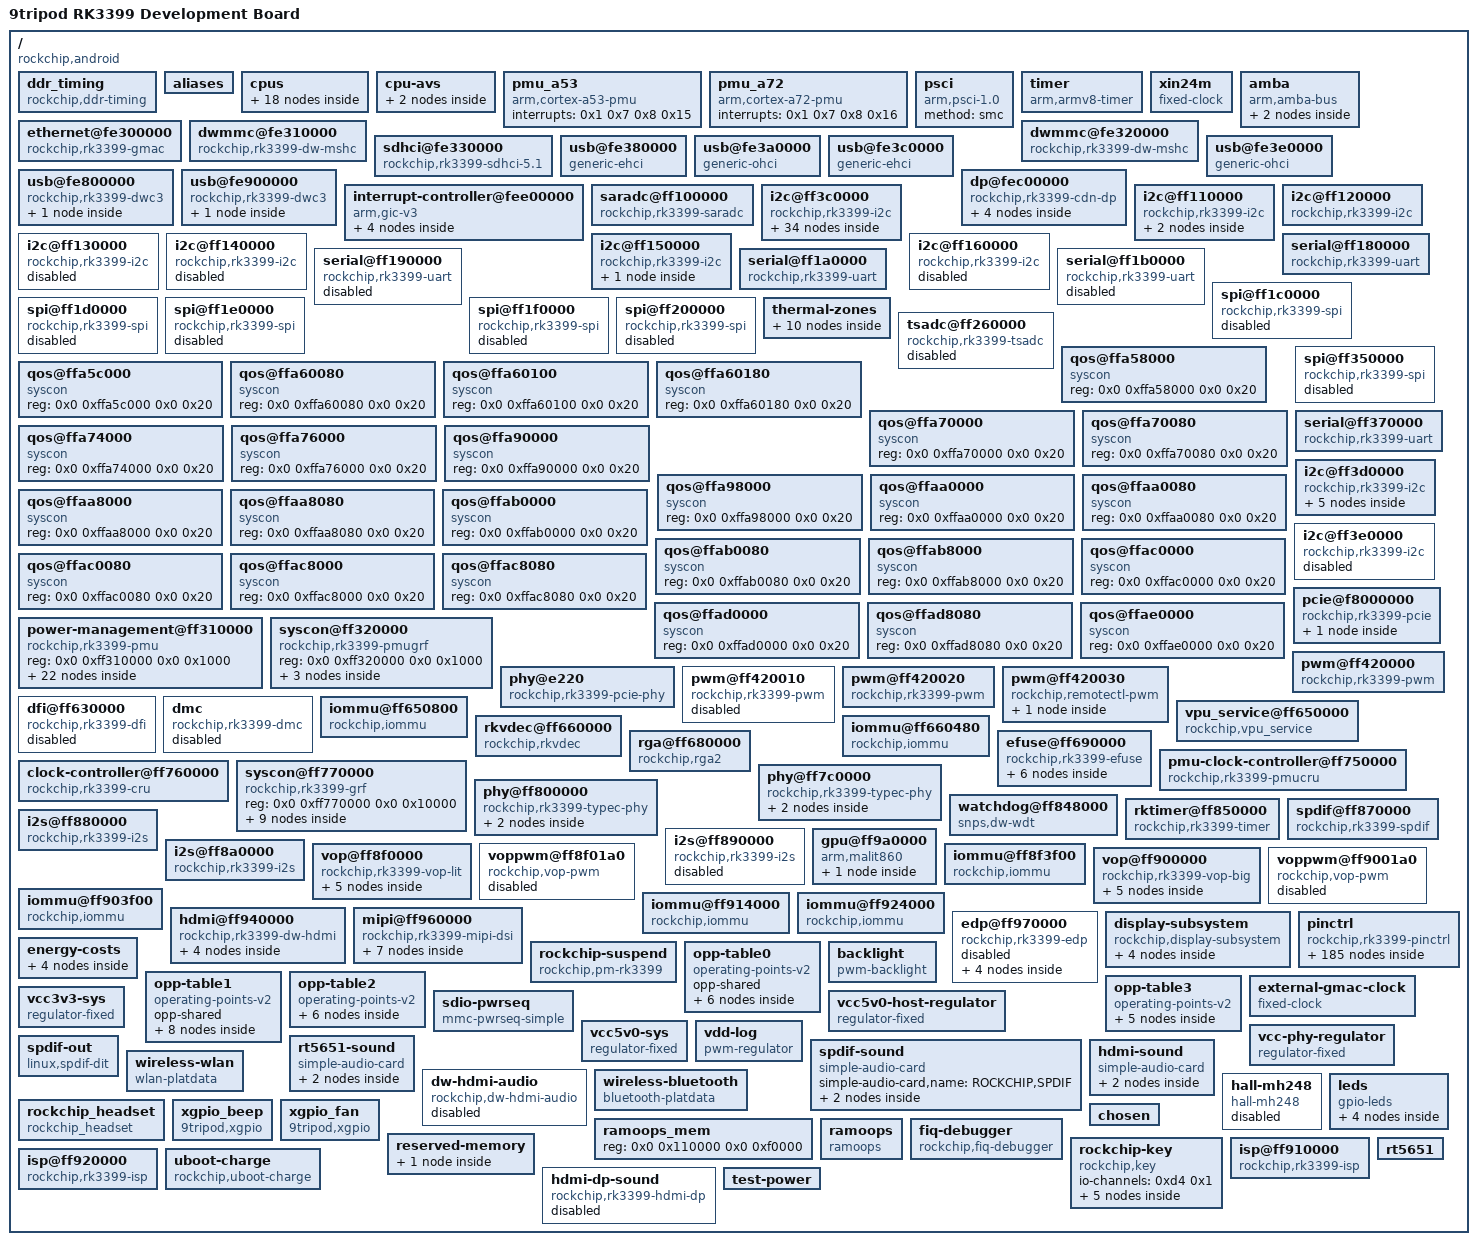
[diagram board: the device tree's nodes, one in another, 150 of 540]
/dts-v1/;

/  {

	compatible = "rockchip,android", "9tripod,x3399-development-board", "rockchip,rk3399";
	interrupt-parent = <0x1>;
	#address-cells = <0x2>;
	#size-cells = <0x2>;
	model = "9tripod RK3399 Development Board";
	ddr_timing {

		compatible = "rockchip,ddr-timing";
		ddr3_speed_bin = <0x15>;
		pd_idle = <0x0>;
		sr_idle = <0x0>;
		sr_mc_gate_idle = <0x0>;
		srpd_lite_idle = <0x0>;
		standby_idle = <0x0>;
		dram_dll_dis_freq = <0x12c>;
		phy_dll_dis_freq = <0x7d>;
		ddr3_odt_dis_freq = <0x14d>;
		ddr3_drv = <0x28>;
		ddr3_odt = <0x78>;
		phy_ddr3_ca_drv = <0x28>;
		phy_ddr3_dq_drv = <0x28>;
		phy_ddr3_odt = <0xf0>;
		lpddr3_odt_dis_freq = <0x14d>;
		lpddr3_drv = <0x22>;
		lpddr3_odt = <0xf0>;
		phy_lpddr3_ca_drv = <0x28>;
		phy_lpddr3_dq_drv = <0x28>;
		phy_lpddr3_odt = <0xf0>;
		lpddr4_odt_dis_freq = <0x14d>;
		lpddr4_drv = <0x3c>;
		lpddr4_dq_odt = <0x28>;
		lpddr4_ca_odt = <0x28>;
		phy_lpddr4_ca_drv = <0x28>;
		phy_lpddr4_ck_cs_drv = <0x50>;
		phy_lpddr4_dq_drv = <0x50>;
		phy_lpddr4_odt = <0x3c>;
		linux,phandle = <0x92>;
		phandle = <0x92>;
	};
	aliases {

		i2c0 = "/i2c@ff3c0000";
		i2c1 = "/i2c@ff110000";
		i2c2 = "/i2c@ff120000";
		i2c3 = "/i2c@ff130000";
		i2c4 = "/i2c@ff3d0000";
		i2c5 = "/i2c@ff140000";
		i2c6 = "/i2c@ff150000";
		i2c7 = "/i2c@ff160000";
		i2c8 = "/i2c@ff3e0000";
		serial0 = "/serial@ff180000";
		serial1 = "/serial@ff190000";
		serial2 = "/serial@ff1a0000";
		serial3 = "/serial@ff1b0000";
		serial4 = "/serial@ff370000";
	};
	cpus {

		#address-cells = <0x2>;
		#size-cells = <0x0>;
		cpu-map {

			cluster0 {

				core0 {

					cpu = <0x2>;
				};
				core1 {

					cpu = <0x3>;
				};
				core2 {

					cpu = <0x4>;
				};
				core3 {

					cpu = <0x5>;
				};
			};
			cluster1 {

				core0 {

					cpu = <0x6>;
				};
				core1 {

					cpu = <0x7>;
				};
			};
		};
		cpu@0 {

			device_type = "cpu";
			compatible = "arm,cortex-a53", "arm,armv8";
			reg = <0x0 0x0>;
			enable-method = "psci";
			#cooling-cells = <0x2>;
			dynamic-power-coefficient = <0x64>;
			clocks = <0x8 0x8>;
			cpu-idle-states = <0x9 0xa>;
			operating-points-v2 = <0xb>;
			sched-energy-costs = <0xc 0xd>;
			cpu-supply = <0xe>;
			linux,phandle = <0x2>;
			phandle = <0x2>;
		};
		cpu@1 {

			device_type = "cpu";
			compatible = "arm,cortex-a53", "arm,armv8";
			reg = <0x0 0x1>;
			enable-method = "psci";
			clocks = <0x8 0x8>;
			cpu-idle-states = <0x9 0xa>;
			operating-points-v2 = <0xb>;
			sched-energy-costs = <0xc 0xd>;
			cpu-supply = <0xe>;
			linux,phandle = <0x3>;
			phandle = <0x3>;
		};
		cpu@2 {

			device_type = "cpu";
			compatible = "arm,cortex-a53", "arm,armv8";
			reg = <0x0 0x2>;
			enable-method = "psci";
			clocks = <0x8 0x8>;
			cpu-idle-states = <0x9 0xa>;
			operating-points-v2 = <0xb>;
			sched-energy-costs = <0xc 0xd>;
			cpu-supply = <0xe>;
			linux,phandle = <0x4>;
			phandle = <0x4>;
		};
		cpu@3 {

			device_type = "cpu";
			compatible = "arm,cortex-a53", "arm,armv8";
			reg = <0x0 0x3>;
			enable-method = "psci";
			clocks = <0x8 0x8>;
			cpu-idle-states = <0x9 0xa>;
			operating-points-v2 = <0xb>;
			sched-energy-costs = <0xc 0xd>;
			cpu-supply = <0xe>;
			linux,phandle = <0x5>;
			phandle = <0x5>;
		};
		cpu@100 {

			device_type = "cpu";
			compatible = "arm,cortex-a72", "arm,armv8";
			reg = <0x0 0x100>;
			enable-method = "psci";
			#cooling-cells = <0x2>;
			dynamic-power-coefficient = <0x1b4>;
			clocks = <0x8 0x9>;
			cpu-idle-states = <0x9 0xa>;
			operating-points-v2 = <0xf>;
			sched-energy-costs = <0x10 0x11>;
			cpu-supply = <0x12>;
			linux,phandle = <0x6>;
			phandle = <0x6>;
		};
		cpu@101 {

			device_type = "cpu";
			compatible = "arm,cortex-a72", "arm,armv8";
			reg = <0x0 0x101>;
			enable-method = "psci";
			clocks = <0x8 0x9>;
			cpu-idle-states = <0x9 0xa>;
			operating-points-v2 = <0xf>;
			sched-energy-costs = <0x10 0x11>;
			cpu-supply = <0x12>;
			linux,phandle = <0x7>;
			phandle = <0x7>;
		};
		idle-states {

			entry-method = "psci";
			cpu-sleep {

				compatible = "arm,idle-state";
				local-timer-stop;
				arm,psci-suspend-param = <0x10000>;
				entry-latency-us = <0x78>;
				exit-latency-us = <0xfa>;
				min-residency-us = <0x384>;
				linux,phandle = <0x9>;
				phandle = <0x9>;
			};
			cluster-sleep {

				compatible = "arm,idle-state";
				local-timer-stop;
				arm,psci-suspend-param = <0x1010000>;
				entry-latency-us = <0x190>;
				exit-latency-us = <0x1f4>;
				min-residency-us = <0x7d0>;
				linux,phandle = <0xa>;
				phandle = <0xa>;
			};
		};
	};
	cpu-avs {

		cluster0-avs {

			cluster-id = <0x0>;
			min-volt = <0xc3500>;
			min-freq = <0x639c0>;
			leakage-adjust-volt = <0x0 0xfe 0x0>;
			nvmem-cells = <0x13>;
			nvmem-cell-names = "cpu_leakage";
		};
		cluster1-avs {

			cluster-id = <0x1>;
			min-volt = <0xc3500>;
			min-freq = <0x639c0>;
			leakage-adjust-volt = <0x0 0xfe 0x0>;
			nvmem-cells = <0x14>;
			nvmem-cell-names = "cpu_leakage";
		};
	};
	pmu_a53 {

		compatible = "arm,cortex-a53-pmu";
		interrupts = <0x1 0x7 0x8 0x15>;
	};
	pmu_a72 {

		compatible = "arm,cortex-a72-pmu";
		interrupts = <0x1 0x7 0x8 0x16>;
	};
	psci {

		compatible = "arm,psci-1.0";
		method = "smc";
	};
	timer {

		compatible = "arm,armv8-timer";
		interrupts = <0x1 0xd 0x8 0x0 0x1 0xe 0x8 0x0 0x1 0xb 0x8 0x0 0x1 0xa 0x8 0x0>;
	};
	xin24m {

		compatible = "fixed-clock";
		clock-frequency = <0x16e3600>;
		clock-output-names = "xin24m";
		#clock-cells = <0x0>;
	};
	amba {

		compatible = "arm,amba-bus";
		#address-cells = <0x2>;
		#size-cells = <0x2>;
		ranges;
		dma-controller@ff6d0000 {

			compatible = "arm,pl330", "arm,primecell";
			reg = <0x0 0xff6d0000 0x0 0x4000>;
			interrupts = <0x0 0x5 0x4 0x0 0x0 0x6 0x4 0x0>;
			#dma-cells = <0x1>;
			clocks = <0x8 0xd3>;
			clock-names = "apb_pclk";
			peripherals-req-type-burst;
			linux,phandle = <0x9a>;
			phandle = <0x9a>;
		};
		dma-controller@ff6e0000 {

			compatible = "arm,pl330", "arm,primecell";
			reg = <0x0 0xff6e0000 0x0 0x4000>;
			interrupts = <0x0 0x7 0x4 0x0 0x0 0x8 0x4 0x0>;
			#dma-cells = <0x1>;
			clocks = <0x8 0xd4>;
			clock-names = "apb_pclk";
			peripherals-req-type-burst;
		};
	};
	ethernet@fe300000 {

		compatible = "rockchip,rk3399-gmac";
		reg = <0x0 0xfe300000 0x0 0x10000>;
		rockchip,grf = <0x17>;
		interrupts = <0x0 0xc 0x4 0x0>;
		interrupt-names = "macirq";
		clocks = <0x8 0x69 0x8 0x67 0x8 0x68 0x8 0x66 0x8 0x6a 0x8 0xd5 0x8 0x166>;
		clock-names = "stmmaceth", "mac_clk_rx", "mac_clk_tx", "clk_mac_ref", "clk_mac_refout", "aclk_mac", "pclk_mac";
		resets = <0x8 0x89>;
		reset-names = "stmmaceth";
		power-domains = <0x18 0x16>;
		status = "okay";
		phy-supply = <0x19>;
		phy-mode = "rgmii";
		clock_in_out = "input";
		snps,reset-gpio = <0x1a 0xf 0x1>;
		snps,reset-active-low;
		snps,reset-delays-us = <0x0 0x2710 0xc350>;
		assigned-clocks = <0x8 0xa6>;
		assigned-clock-parents = <0x1b>;
		pinctrl-names = "default";
		pinctrl-0 = <0x1c>;
		tx_delay = <0x28>;
		rx_delay = <0x11>;
	};
	dwmmc@fe310000 {

		compatible = "rockchip,rk3399-dw-mshc", "rockchip,rk3288-dw-mshc";
		reg = <0x0 0xfe310000 0x0 0x4000>;
		interrupts = <0x0 0x40 0x4 0x0>;
		clock-freq-min-max = <0x30d40 0x2faf080>;
		clocks = <0x8 0x1ee 0x8 0x4d 0x8 0x9c 0x8 0x9d>;
		clock-names = "biu", "ciu", "ciu-drive", "ciu-sample";
		fifo-depth = <0x100>;
		power-domains = <0x18 0x1c>;
		status = "okay";
		clock-frequency = <0x2faf080>;
		supports-sdio;
		bus-width = <0x4>;
		disable-wp;
		cap-sd-highspeed;
		cap-sdio-irq;
		keep-power-in-suspend;
		mmc-pwrseq = <0x1d>;
		non-removable;
		num-slots = <0x1>;
		pinctrl-names = "default";
		pinctrl-0 = <0x1e 0x1f 0x20>;
		sd-uhs-sdr104;
	};
	dwmmc@fe320000 {

		compatible = "rockchip,rk3399-dw-mshc", "rockchip,rk3288-dw-mshc";
		reg = <0x0 0xfe320000 0x0 0x4000>;
		interrupts = <0x0 0x41 0x4 0x0>;
		clock-freq-min-max = <0x186a0 0x5f5e100>;
		clocks = <0x8 0x1ce 0x8 0x4c 0x8 0x9a 0x8 0x9b>;
		clock-names = "biu", "ciu", "ciu-drive", "ciu-sample";
		fifo-depth = <0x100>;
		power-domains = <0x18 0x1b>;
		status = "okay";
		clock-frequency = <0x5f5e100>;
		supports-sd;
		bus-width = <0x4>;
		cap-mmc-highspeed;
		cap-sd-highspeed;
		disable-wp;
		num-slots = <0x1>;
		vqmmc-supply = <0x21>;
		pinctrl-names = "default";
		pinctrl-0 = <0x22 0x23 0x24 0x25>;
		card-detect-delay = <0x320>;
	};
	sdhci@fe330000 {

		compatible = "rockchip,rk3399-sdhci-5.1", "arasan,sdhci-5.1";
		reg = <0x0 0xfe330000 0x0 0x10000>;
		interrupts = <0x0 0xb 0x4 0x0>;
		arasan,soc-ctl-syscon = <0x17>;
		assigned-clocks = <0x8 0x4e>;
		assigned-clock-rates = <0xbebc200>;
		clocks = <0x8 0x4e 0x8 0xf0>;
		clock-names = "clk_xin", "clk_ahb";
		clock-output-names = "emmc_cardclock";
		#clock-cells = <0x0>;
		phys = <0x26>;
		phy-names = "phy_arasan";
		power-domains = <0x18 0x17>;
		status = "okay";
		bus-width = <0x8>;
		mmc-hs400-1_8v;
		supports-emmc;
		non-removable;
		keep-power-in-suspend;
		mmc-hs400-enhanced-strobe;
		assigned-clock-parents = <0x8 0x5>;
		linux,phandle = <0x98>;
		phandle = <0x98>;
	};
	usb@fe380000 {

		compatible = "generic-ehci";
		reg = <0x0 0xfe380000 0x0 0x20000>;
		interrupts = <0x0 0x1a 0x4 0x0>;
		clocks = <0x8 0x1c8 0x8 0x1c9 0x8 0xa8>;
		clock-names = "hclk_host0", "hclk_host0_arb", "usbphy0_480m";
		phys = <0x27>;
		phy-names = "usb";
		power-domains = <0x18 0xe>;
		status = "okay";
	};
	usb@fe3a0000 {

		compatible = "generic-ohci";
		reg = <0x0 0xfe3a0000 0x0 0x20000>;
		interrupts = <0x0 0x1c 0x4 0x0>;
		clocks = <0x8 0x1c8 0x8 0x1c9 0x8 0xa8>;
		clock-names = "hclk_host0", "hclk_host0_arb", "usbphy0_480m";
		phys = <0x27>;
		phy-names = "usb";
		power-domains = <0x18 0xe>;
		status = "okay";
	};
	usb@fe3c0000 {

		compatible = "generic-ehci";
		reg = <0x0 0xfe3c0000 0x0 0x20000>;
		interrupts = <0x0 0x1e 0x4 0x0>;
		clocks = <0x8 0x1ca 0x8 0x1cb 0x8 0xa9>;
		clock-names = "hclk_host1", "hclk_host1_arb", "usbphy1_480m";
		phys = <0x28>;
		phy-names = "usb";
		power-domains = <0x18 0xe>;
		status = "okay";
	};
	usb@fe3e0000 {

		compatible = "generic-ohci";
		reg = <0x0 0xfe3e0000 0x0 0x20000>;
		interrupts = <0x0 0x20 0x4 0x0>;
		clocks = <0x8 0x1ca 0x8 0x1cb 0x8 0xa9>;
		clock-names = "hclk_host1", "hclk_host1_arb", "usbphy1_480m";
		phys = <0x28>;
		phy-names = "usb";
		power-domains = <0x18 0xe>;
		status = "okay";
	};
	usb@fe800000 {

		compatible = "rockchip,rk3399-dwc3";
		clocks = <0x8 0x81 0x8 0x83 0x8 0xf6 0x8 0xf9>;
		clock-names = "ref_clk", "suspend_clk", "bus_clk", "grf_clk";
		power-domains = <0x18 0x18>;
		resets = <0x8 0x125>;
		reset-names = "usb3-otg";
		#address-cells = <0x2>;
		#size-cells = <0x2>;
		ranges;
		status = "okay";
		extcon = <0x29>;
		dwc3@fe800000 {

			compatible = "snps,dwc3";
			reg = <0x0 0xfe800000 0x0 0x100000>;
			interrupts = <0x0 0x69 0x4 0x0>;
			dr_mode = "otg";
			phys = <0x2a 0x2b>;
			phy-names = "usb2-phy", "usb3-phy";
			phy_type = "utmi_wide";
			snps,dis_enblslpm_quirk;
			snps,dis-u2-freeclk-exists-quirk;
			snps,dis_u2_susphy_quirk;
			snps,dis-del-phy-power-chg-quirk;
			snps,xhci-slow-suspend-quirk;
			status = "okay";
		};
	};
	usb@fe900000 {

		compatible = "rockchip,rk3399-dwc3";
		clocks = <0x8 0x82 0x8 0x84 0x8 0xf7 0x8 0xf9>;
		clock-names = "ref_clk", "suspend_clk", "bus_clk", "grf_clk";
		power-domains = <0x18 0x18>;
		resets = <0x8 0x126>;
		reset-names = "usb3-otg";
		#address-cells = <0x2>;
		#size-cells = <0x2>;
		ranges;
		status = "okay";
		dwc3@fe900000 {

			compatible = "snps,dwc3";
			reg = <0x0 0xfe900000 0x0 0x100000>;
			interrupts = <0x0 0x6e 0x4 0x0>;
			dr_mode = "host";
			phys = <0x2c 0x2d>;
			phy-names = "usb2-phy", "usb3-phy";
			phy_type = "utmi_wide";
			snps,dis_enblslpm_quirk;
			snps,dis-u2-freeclk-exists-quirk;
			snps,dis_u2_susphy_quirk;
			snps,dis-del-phy-power-chg-quirk;
			snps,xhci-slow-suspend-quirk;
			status = "okay";
		};
	};
	dp@fec00000 {

		compatible = "rockchip,rk3399-cdn-dp";
		reg = <0x0 0xfec00000 0x0 0x100000>;
		interrupts = <0x0 0x9 0x4>;
		clocks = <0x8 0x72 0x8 0x175 0x8 0xa1 0x8 0x16f>;
		clock-names = "core-clk", "pclk", "spdif", "grf";
		assigned-clocks = <0x8 0x72>;
		assigned-clock-rates = <0x5f5e100>;
		power-domains = <0x18 0x15>;
		phys = <0x2e>;
		resets = <0x8 0x103 0x8 0x148 0x8 0x14a 0x8 0xfd>;
		reset-names = "spdif", "dptx", "apb", "core";
		rockchip,grf = <0x17>;
		#address-cells = <0x1>;
		#size-cells = <0x0>;
		#sound-dai-cells = <0x1>;
		status = "okay";
		extcon = <0x29>;
		linux,phandle = <0xdc>;
		phandle = <0xdc>;
		ports {

			#address-cells = <0x1>;
			#size-cells = <0x0>;
			port {

				#address-cells = <0x1>;
				#size-cells = <0x0>;
				endpoint@0 {

					reg = <0x0>;
					remote-endpoint = <0x2f>;
					status = "okay";
					linux,phandle = <0xaa>;
					phandle = <0xaa>;
				};
				endpoint@1 {

					reg = <0x1>;
					remote-endpoint = <0x30>;
					linux,phandle = <0xa4>;
					phandle = <0xa4>;
				};
			};
		};
	};
	interrupt-controller@fee00000 {

		compatible = "arm,gic-v3";
		#interrupt-cells = <0x4>;
		#address-cells = <0x2>;
		#size-cells = <0x2>;
		ranges;
		interrupt-controller;
		reg = <0x0 0xfee00000 0x0 0x10000 0x0 0xfef00000 0x0 0xc0000 0x0 0xfff00000 0x0 0x10000 0x0 0xfff10000 0x0 0x10000 0x0 0xfff20000 0x0 0x10000>;
		interrupts = <0x1 0x9 0x4 0x0>;
		linux,phandle = <0x1>;
		phandle = <0x1>;
		interrupt-controller@fee20000 {

			compatible = "arm,gic-v3-its";
			msi-controller;
			reg = <0x0 0xfee20000 0x0 0x20000>;
			linux,phandle = <0x87>;
			phandle = <0x87>;
		};
		ppi-partitions {

			interrupt-partition-0 {

				affinity = <0x2 0x3 0x4 0x5>;
				linux,phandle = <0x15>;
				phandle = <0x15>;
			};
			interrupt-partition-1 {

				affinity = <0x6 0x7>;
				linux,phandle = <0x16>;
				phandle = <0x16>;
			};
		};
	};
	saradc@ff100000 {

		compatible = "rockchip,rk3399-saradc";
		reg = <0x0 0xff100000 0x0 0x100>;
		interrupts = <0x0 0x3e 0x4 0x0>;
		#io-channel-cells = <0x1>;
		clocks = <0x8 0x50 0x8 0x165>;
		clock-names = "saradc", "apb_pclk";
		resets = <0x8 0xd4>;
		reset-names = "saradc-apb";
		status = "okay";
		linux,phandle = <0xd4>;
		phandle = <0xd4>;
	};
	i2c@ff3c0000 {

		compatible = "rockchip,rk3399-i2c";
		reg = <0x0 0xff3c0000 0x0 0x1000>;
		clocks = <0x31 0x9 0x31 0x1b>;
		clock-names = "i2c", "pclk";
		interrupts = <0x0 0x39 0x4 0x0>;
		pinctrl-names = "default";
		pinctrl-0 = <0x32>;
		#address-cells = <0x1>;
		#size-cells = <0x0>;
		status = "okay";
		i2c-scl-rising-time-ns = <0xa8>;
		i2c-scl-falling-time-ns = <0x4>;
		clock-frequency = <0x61a80>;
		syr827@40 {

			compatible = "silergy,syr827";
			reg = <0x40>;
			vin-supply = <0x33>;
			regulator-compatible = "fan53555-reg";
			regulator-name = "vdd_cpu_b";
			regulator-min-microvolt = <0xadf34>;
			regulator-max-microvolt = <0x16e360>;
			regulator-ramp-delay = <0x3e8>;
			fcs,suspend-voltage-selector = <0x1>;
			regulator-always-on;
			regulator-boot-on;
			regulator-initial-state = <0x3>;
			linux,phandle = <0x12>;
			phandle = <0x12>;
			regulator-state-mem {

				regulator-off-in-suspend;
			};
		};
		syr828@41 {

			compatible = "silergy,syr828";
			reg = <0x41>;
			vin-supply = <0x33>;
			regulator-compatible = "fan53555-reg";
			regulator-name = "vdd_gpu";
			regulator-min-microvolt = <0xadf34>;
			regulator-max-microvolt = <0x16e360>;
			regulator-ramp-delay = <0x3e8>;
			fcs,suspend-voltage-selector = <0x1>;
			regulator-always-on;
			regulator-boot-on;
			regulator-initial-state = <0x3>;
			linux,phandle = <0x9f>;
			phandle = <0x9f>;
			regulator-state-mem {

				regulator-off-in-suspend;
			};
		};
		pmic@1b {

			compatible = "rockchip,rk808";
			reg = <0x1b>;
			interrupt-parent = <0x34>;
			interrupts = <0x15 0x8>;
			pinctrl-names = "default";
			pinctrl-0 = <0x35 0x36>;
			rockchip,system-power-controller;
			wakeup-source;
			#clock-cells = <0x1>;
			clock-output-names = "xin32k", "rk808-clkout2";
			vcc1-supply = <0x37>;
			vcc2-supply = <0x37>;
			vcc3-supply = <0x37>;
			vcc4-supply = <0x37>;
			vcc6-supply = <0x37>;
			vcc7-supply = <0x37>;
			vcc8-supply = <0x37>;
			vcc9-supply = <0x37>;
			vcc10-supply = <0x37>;
			vcc11-supply = <0x37>;
			vcc12-supply = <0x37>;
			vddio-supply = <0x38>;
			linux,phandle = <0xbf>;
			phandle = <0xbf>;
			regulators {

				DCDC_REG1 {

					regulator-always-on;
					regulator-boot-on;
					regulator-min-microvolt = <0xb71b0>;
					regulator-max-microvolt = <0x149970>;
					regulator-ramp-delay = <0x1771>;
					regulator-name = "vdd_center";
					regulator-state-mem {

						regulator-off-in-suspend;
					};
				};
				DCDC_REG2 {

					regulator-always-on;
					regulator-boot-on;
					regulator-min-microvolt = <0xb71b0>;
					regulator-max-microvolt = <0x149970>;
					regulator-ramp-delay = <0x1771>;
					regulator-name = "vdd_cpu_l";
					linux,phandle = <0xe>;
					phandle = <0xe>;
					regulator-state-mem {

						regulator-off-in-suspend;
					};
				};
				DCDC_REG3 {

					regulator-always-on;
					regulator-boot-on;
					regulator-name = "vcc_ddr";
					regulator-state-mem {

						regulator-on-in-suspend;
					};
				};
				DCDC_REG4 {

					regulator-always-on;
					regulator-boot-on;
					regulator-min-microvolt = <0x1b7740>;
					regulator-max-microvolt = <0x1b7740>;
					regulator-name = "vcc_1v8";
					linux,phandle = <0x79>;
					phandle = <0x79>;
					regulator-state-mem {

						regulator-on-in-suspend;
						regulator-suspend-microvolt = <0x1b7740>;
					};
				};
				LDO_REG1 {

					regulator-always-on;
					regulator-boot-on;
					regulator-min-microvolt = <0x1b7740>;
					regulator-max-microvolt = <0x1b7740>;
					regulator-name = "vcc1v8_dvp";
					regulator-state-mem {

						regulator-off-in-suspend;
					};
				};
				LDO_REG2 {

					regulator-always-on;
					regulator-boot-on;
					regulator-min-microvolt = <0x2dc6c0>;
					regulator-max-microvolt = <0x2dc6c0>;
					regulator-name = "vcc3v0_tp";
					regulator-state-mem {

						regulator-off-in-suspend;
					};
				};
				LDO_REG3 {

					regulator-always-on;
					regulator-boot-on;
					regulator-min-microvolt = <0x1b7740>;
					regulator-max-microvolt = <0x1b7740>;
					regulator-name = "vcc1v8_pmu";
					linux,phandle = <0x38>;
					phandle = <0x38>;
					regulator-state-mem {

						regulator-on-in-suspend;
						regulator-suspend-microvolt = <0x1b7740>;
					};
				};
				LDO_REG4 {

					regulator-always-on;
					regulator-boot-on;
					regulator-min-microvolt = <0x1b7740>;
					regulator-max-microvolt = <0x325aa0>;
					regulator-name = "vcc_sd";
					linux,phandle = <0x21>;
					phandle = <0x21>;
					regulator-state-mem {

						regulator-on-in-suspend;
						regulator-suspend-microvolt = <0x325aa0>;
					};
				};
				LDO_REG5 {

					regulator-always-on;
					regulator-boot-on;
					regulator-min-microvolt = <0x2dc6c0>;
					regulator-max-microvolt = <0x2dc6c0>;
					regulator-name = "vcca3v0_codec";
					regulator-state-mem {

						regulator-off-in-suspend;
					};
				};
				LDO_REG6 {

					regulator-always-on;
					regulator-boot-on;
					regulator-min-microvolt = <0x16e360>;
					regulator-max-microvolt = <0x16e360>;
					regulator-name = "vcc_1v5";
					regulator-state-mem {

						regulator-on-in-suspend;
						regulator-suspend-microvolt = <0x16e360>;
					};
				};
				LDO_REG7 {

					regulator-always-on;
					regulator-boot-on;
					regulator-min-microvolt = <0x1b7740>;
					regulator-max-microvolt = <0x1b7740>;
					regulator-name = "vcca1v8_codec";
					linux,phandle = <0x96>;
					phandle = <0x96>;
					regulator-state-mem {

						regulator-off-in-suspend;
					};
				};
				LDO_REG8 {

					regulator-always-on;
					regulator-boot-on;
					regulator-min-microvolt = <0x2dc6c0>;
					regulator-max-microvolt = <0x2dc6c0>;
					regulator-name = "vcc_3v0";
					linux,phandle = <0x97>;
					phandle = <0x97>;
					regulator-state-mem {

						regulator-on-in-suspend;
						regulator-suspend-microvolt = <0x2dc6c0>;
					};
				};
				SWITCH_REG1 {

					regulator-always-on;
					regulator-boot-on;
					regulator-name = "vcc3v3_s3";
					regulator-state-mem {

						regulator-off-in-suspend;
					};
				};
				SWITCH_REG2 {

					regulator-always-on;
					regulator-boot-on;
					regulator-name = "vcc3v3_s0";
					regulator-state-mem {

						regulator-off-in-suspend;
					};
				};
			};
		};
	};
	i2c@ff110000 {

		compatible = "rockchip,rk3399-i2c";
		reg = <0x0 0xff110000 0x0 0x1000>;
		clocks = <0x8 0x41 0x8 0x155>;
		clock-names = "i2c", "pclk";
		interrupts = <0x0 0x3b 0x4 0x0>;
		pinctrl-names = "default";
		pinctrl-0 = <0x39>;
		#address-cells = <0x1>;
		#size-cells = <0x0>;
		status = "okay";
		i2c-scl-rising-time-ns = <0x12c>;
		i2c-scl-falling-time-ns = <0xf>;
		rt5651@1a {

			#sound-dai-cells = <0x0>;
			compatible = "realtek,rt5651";
			reg = <0x1a>;
			clocks = <0x8 0x59>;
			clock-names = "mclk";
			spk-con-gpio = <0x3a 0xb 0x0>;
			linux,phandle = <0xc4>;
			phandle = <0xc4>;
		};
		gslx680@40 {

			compatible = "9tripod,gslx680";
			reg = <0x40>;
			touch-gpio = <0x34 0x14 0x1>;
			reset-gpio = <0x34 0x9 0x1>;
			max-x = <0x400>;
			max-y = <0x258>;
		};
	};
	i2c@ff120000 {

		compatible = "rockchip,rk3399-i2c";
		reg = <0x0 0xff120000 0x0 0x1000>;
		clocks = <0x8 0x42 0x8 0x156>;
		clock-names = "i2c", "pclk";
		interrupts = <0x0 0x23 0x4 0x0>;
		pinctrl-names = "default";
		pinctrl-0 = <0x3b>;
		#address-cells = <0x1>;
		#size-cells = <0x0>;
		status = "okay";
	};
	i2c@ff130000 {

		compatible = "rockchip,rk3399-i2c";
		reg = <0x0 0xff130000 0x0 0x1000>;
		clocks = <0x8 0x43 0x8 0x157>;
		clock-names = "i2c", "pclk";
		interrupts = <0x0 0x22 0x4 0x0>;
		pinctrl-names = "default";
		pinctrl-0 = <0x3c>;
		#address-cells = <0x1>;
		#size-cells = <0x0>;
		status = "disabled";
	};
	i2c@ff140000 {

		compatible = "rockchip,rk3399-i2c";
		reg = <0x0 0xff140000 0x0 0x1000>;
		clocks = <0x8 0x44 0x8 0x158>;
		clock-names = "i2c", "pclk";
		interrupts = <0x0 0x26 0x4 0x0>;
		pinctrl-names = "default";
		pinctrl-0 = <0x3d>;
		#address-cells = <0x1>;
		#size-cells = <0x0>;
		status = "disabled";
	};
	i2c@ff150000 {

		compatible = "rockchip,rk3399-i2c";
		reg = <0x0 0xff150000 0x0 0x1000>;
		clocks = <0x8 0x45 0x8 0x159>;
		clock-names = "i2c", "pclk";
		interrupts = <0x0 0x25 0x4 0x0>;
		pinctrl-names = "default";
		pinctrl-0 = <0x3e>;
		#address-cells = <0x1>;
		#size-cells = <0x0>;
		status = "okay";
		i2c-scl-rising-time-ns = <0x159>;
		i2c-scl-falling-time-ns = <0xb>;
		clock-frequency = <0x4e20>;
		xic@20 {

			compatible = "9tripod,xic";
			reg = <0x20>;
		};
	};
	i2c@ff160000 {

		compatible = "rockchip,rk3399-i2c";
		reg = <0x0 0xff160000 0x0 0x1000>;
		clocks = <0x8 0x46 0x8 0x15a>;
		clock-names = "i2c", "pclk";
		interrupts = <0x0 0x24 0x4 0x0>;
		pinctrl-names = "default";
		pinctrl-0 = <0x3f>;
		#address-cells = <0x1>;
		#size-cells = <0x0>;
		status = "disabled";
	};
	serial@ff180000 {

		compatible = "rockchip,rk3399-uart", "snps,dw-apb-uart";
		reg = <0x0 0xff180000 0x0 0x100>;
		clocks = <0x8 0x51 0x8 0x160>;
		clock-names = "baudclk", "apb_pclk";
		interrupts = <0x0 0x63 0x4 0x0>;
		reg-shift = <0x2>;
		reg-io-width = <0x4>;
		pinctrl-names = "default";
		pinctrl-0 = <0x40 0x41>;
		status = "okay";
		assigned-clocks = <0x8 0xac>;
		assigned-clock-parents = <0x8 0x5>;
	};
	serial@ff190000 {

		compatible = "rockchip,rk3399-uart", "snps,dw-apb-uart";
		reg = <0x0 0xff190000 0x0 0x100>;
		clocks = <0x8 0x52 0x8 0x161>;
		clock-names = "baudclk", "apb_pclk";
		interrupts = <0x0 0x62 0x4 0x0>;
		reg-shift = <0x2>;
		reg-io-width = <0x4>;
		pinctrl-names = "default";
		pinctrl-0 = <0x42>;
		status = "disabled";
		assigned-clocks = <0x8 0xad>;
		assigned-clock-parents = <0x8 0x5>;
	};
	serial@ff1a0000 {

		compatible = "rockchip,rk3399-uart", "snps,dw-apb-uart";
		reg = <0x0 0xff1a0000 0x0 0x100>;
		clocks = <0x8 0x53 0x8 0x162>;
		clock-names = "baudclk", "apb_pclk";
		interrupts = <0x0 0x64 0x4 0x0>;
		reg-shift = <0x2>;
		reg-io-width = <0x4>;
		pinctrl-names = "default";
		pinctrl-0 = <0x43>;
		status = "okay";
		assigned-clocks = <0x8 0xad>;
		assigned-clock-parents = <0x8 0x5>;
	};
	serial@ff1b0000 {

		compatible = "rockchip,rk3399-uart", "snps,dw-apb-uart";
		reg = <0x0 0xff1b0000 0x0 0x100>;
		clocks = <0x8 0x54 0x8 0x163>;
		clock-names = "baudclk", "apb_pclk";
		interrupts = <0x0 0x65 0x4 0x0>;
		reg-shift = <0x2>;
		reg-io-width = <0x4>;
		pinctrl-names = "default";
		pinctrl-0 = <0x44 0x45 0x46>;
		status = "disabled";
		assigned-clocks = <0x8 0xad>;
		assigned-clock-parents = <0x8 0x5>;
	};
	spi@ff1c0000 {

		compatible = "rockchip,rk3399-spi", "rockchip,rk3066-spi";
		reg = <0x0 0xff1c0000 0x0 0x1000>;
		clocks = <0x8 0x47 0x8 0x15b>;
		clock-names = "spiclk", "apb_pclk";
		interrupts = <0x0 0x44 0x4 0x0>;
		pinctrl-names = "default";
		pinctrl-0 = <0x47 0x48 0x49 0x4a>;
		#address-cells = <0x1>;
		#size-cells = <0x0>;
		status = "disabled";
	};
	spi@ff1d0000 {

		compatible = "rockchip,rk3399-spi", "rockchip,rk3066-spi";
		reg = <0x0 0xff1d0000 0x0 0x1000>;
		clocks = <0x8 0x48 0x8 0x15c>;
		clock-names = "spiclk", "apb_pclk";
		interrupts = <0x0 0x35 0x4 0x0>;
		pinctrl-names = "default";
		pinctrl-0 = <0x4b 0x4c 0x4d 0x4e>;
		#address-cells = <0x1>;
		#size-cells = <0x0>;
		status = "disabled";
	};
	spi@ff1e0000 {

		compatible = "rockchip,rk3399-spi", "rockchip,rk3066-spi";
		reg = <0x0 0xff1e0000 0x0 0x1000>;
		clocks = <0x8 0x49 0x8 0x15d>;
		clock-names = "spiclk", "apb_pclk";
		interrupts = <0x0 0x34 0x4 0x0>;
		pinctrl-names = "default";
		pinctrl-0 = <0x4f 0x50 0x51 0x52>;
		#address-cells = <0x1>;
		#size-cells = <0x0>;
		status = "disabled";
	};
	spi@ff1f0000 {

		compatible = "rockchip,rk3399-spi", "rockchip,rk3066-spi";
		reg = <0x0 0xff1f0000 0x0 0x1000>;
		clocks = <0x8 0x4a 0x8 0x15e>;
		clock-names = "spiclk", "apb_pclk";
		interrupts = <0x0 0x43 0x4 0x0>;
		pinctrl-names = "default";
		pinctrl-0 = <0x53 0x54 0x55 0x56>;
		#address-cells = <0x1>;
		#size-cells = <0x0>;
		status = "disabled";
	};
	spi@ff200000 {

		compatible = "rockchip,rk3399-spi", "rockchip,rk3066-spi";
		reg = <0x0 0xff200000 0x0 0x1000>;
		clocks = <0x8 0x4b 0x8 0x15f>;
		clock-names = "spiclk", "apb_pclk";
		interrupts = <0x0 0x84 0x4 0x0>;
		pinctrl-names = "default";
		pinctrl-0 = <0x57 0x58 0x59 0x5a>;
		#address-cells = <0x1>;
		#size-cells = <0x0>;
		status = "disabled";
	};
	thermal-zones {

		soc-thermal {

			polling-delay-passive = <0x14>;
			polling-delay = <0x3e8>;
			sustainable-power = <0x3e8>;
			thermal-sensors = <0x5b 0x0>;
			trips {

				trip-point@0 {

					temperature = <0x14c08>;
					hysteresis = <0x7d0>;
					type = "passive";
				};
				trip-point@1 {

					temperature = <0x186a0>;
					hysteresis = <0x7d0>;
					type = "passive";
					linux,phandle = <0x5c>;
					phandle = <0x5c>;
				};
				soc-crit {

					temperature = <0x19a28>;
					hysteresis = <0x7d0>;
					type = "critical";
				};
			};
			cooling-maps {

				map0 {

					trip = <0x5c>;
					cooling-device = <0x2 0xffffffff 0xffffffff>;
					contribution = <0x1000>;
				};
				map1 {

					trip = <0x5c>;
					cooling-device = <0x6 0xffffffff 0xffffffff>;
					contribution = <0x400>;
				};
				map2 {

					trip = <0x5c>;
					cooling-device = <0x5d 0xffffffff 0xffffffff>;
					contribution = <0x1000>;
				};
			};
		};
		gpu-thermal {

			polling-delay-passive = <0x64>;
			polling-delay = <0x3e8>;
			thermal-sensors = <0x5b 0x1>;
		};
	};
	tsadc@ff260000 {

		compatible = "rockchip,rk3399-tsadc";
		reg = <0x0 0xff260000 0x0 0x100>;
		interrupts = <0x0 0x61 0x4 0x0>;
		rockchip,grf = <0x17>;
		clocks = <0x8 0x4f 0x8 0x164>;
		clock-names = "tsadc", "apb_pclk";
		assigned-clocks = <0x8 0x4f>;
		assigned-clock-rates = <0xb71b0>;
		resets = <0x8 0xe8>;
		reset-names = "tsadc-apb";
		pinctrl-names = "init", "default", "sleep";
		pinctrl-0 = <0x5e>;
		pinctrl-1 = <0x5f>;
		pinctrl-2 = <0x5e>;
		#thermal-sensor-cells = <0x1>;
		rockchip,hw-tshut-temp = <0x1adb0>;
		status = "disabled";
		rockchip,hw-tshut-mode = <0x1>;
		rockchip,hw-tshut-polarity = <0x1>;
		linux,phandle = <0x5b>;
		phandle = <0x5b>;
	};
	qos@ffa58000 {

		compatible = "syscon";
		reg = <0x0 0xffa58000 0x0 0x20>;
		linux,phandle = <0x67>;
		phandle = <0x67>;
	};
	qos@ffa5c000 {

		compatible = "syscon";
		reg = <0x0 0xffa5c000 0x0 0x20>;
		linux,phandle = <0x68>;
		phandle = <0x68>;
	};
	qos@ffa60080 {

		compatible = "syscon";
		reg = <0x0 0xffa60080 0x0 0x20>;
		linux,phandle = <0x6a>;
		phandle = <0x6a>;
	};
	qos@ffa60100 {

		compatible = "syscon";
		reg = <0x0 0xffa60100 0x0 0x20>;
		linux,phandle = <0x6b>;
		phandle = <0x6b>;
	};
	qos@ffa60180 {

		compatible = "syscon";
		reg = <0x0 0xffa60180 0x0 0x20>;
		linux,phandle = <0x6c>;
		phandle = <0x6c>;
	};
	qos@ffa70000 {

		compatible = "syscon";
		reg = <0x0 0xffa70000 0x0 0x20>;
		linux,phandle = <0x6f>;
		phandle = <0x6f>;
	};
	qos@ffa70080 {

		compatible = "syscon";
		reg = <0x0 0xffa70080 0x0 0x20>;
		linux,phandle = <0x70>;
		phandle = <0x70>;
	};
	qos@ffa74000 {

		compatible = "syscon";
		reg = <0x0 0xffa74000 0x0 0x20>;
		linux,phandle = <0x6d>;
		phandle = <0x6d>;
	};
	qos@ffa76000 {

		compatible = "syscon";
		reg = <0x0 0xffa76000 0x0 0x20>;
		linux,phandle = <0x6e>;
		phandle = <0x6e>;
	};
	qos@ffa90000 {

		compatible = "syscon";
		reg = <0x0 0xffa90000 0x0 0x20>;
		linux,phandle = <0x71>;
		phandle = <0x71>;
	};
	qos@ffa98000 {

		compatible = "syscon";
		reg = <0x0 0xffa98000 0x0 0x20>;
		linux,phandle = <0x60>;
		phandle = <0x60>;
	};
	qos@ffaa0000 {

		compatible = "syscon";
		reg = <0x0 0xffaa0000 0x0 0x20>;
		linux,phandle = <0x72>;
		phandle = <0x72>;
	};
	qos@ffaa0080 {

		compatible = "syscon";
		reg = <0x0 0xffaa0080 0x0 0x20>;
		linux,phandle = <0x73>;
		phandle = <0x73>;
	};
	qos@ffaa8000 {

		compatible = "syscon";
		reg = <0x0 0xffaa8000 0x0 0x20>;
		linux,phandle = <0x74>;
		phandle = <0x74>;
	};
	qos@ffaa8080 {

		compatible = "syscon";
		reg = <0x0 0xffaa8080 0x0 0x20>;
		linux,phandle = <0x75>;
		phandle = <0x75>;
	};
	qos@ffab0000 {

		compatible = "syscon";
		reg = <0x0 0xffab0000 0x0 0x20>;
		linux,phandle = <0x61>;
		phandle = <0x61>;
	};
	qos@ffab0080 {

		compatible = "syscon";
		reg = <0x0 0xffab0080 0x0 0x20>;
		linux,phandle = <0x62>;
		phandle = <0x62>;
	};
	qos@ffab8000 {

		compatible = "syscon";
		reg = <0x0 0xffab8000 0x0 0x20>;
		linux,phandle = <0x63>;
		phandle = <0x63>;
	};
	qos@ffac0000 {

		compatible = "syscon";
		reg = <0x0 0xffac0000 0x0 0x20>;
		linux,phandle = <0x64>;
		phandle = <0x64>;
	};
	qos@ffac0080 {

		compatible = "syscon";
		reg = <0x0 0xffac0080 0x0 0x20>;
		linux,phandle = <0x65>;
		phandle = <0x65>;
	};
	qos@ffac8000 {

		compatible = "syscon";
		reg = <0x0 0xffac8000 0x0 0x20>;
		linux,phandle = <0x76>;
		phandle = <0x76>;
	};
	qos@ffac8080 {

		compatible = "syscon";
		reg = <0x0 0xffac8080 0x0 0x20>;
		linux,phandle = <0x77>;
		phandle = <0x77>;
	};
	qos@ffad0000 {

		compatible = "syscon";
		reg = <0x0 0xffad0000 0x0 0x20>;
		linux,phandle = <0x78>;
		phandle = <0x78>;
	};
	qos@ffad8080 {

		compatible = "syscon";
		reg = <0x0 0xffad8080 0x0 0x20>;
		linux,phandle = <0x69>;
		phandle = <0x69>;
	};
	qos@ffae0000 {

		compatible = "syscon";
		reg = <0x0 0xffae0000 0x0 0x20>;
		linux,phandle = <0x66>;
		phandle = <0x66>;
	};
	power-management@ff310000 {

		compatible = "rockchip,rk3399-pmu", "syscon", "simple-mfd";
		reg = <0x0 0xff310000 0x0 0x1000>;
		power-controller {

			compatible = "rockchip,rk3399-power-controller";
			#power-domain-cells = <0x1>;
			#address-cells = <0x1>;
			#size-cells = <0x0>;
			linux,phandle = <0x18>;
			phandle = <0x18>;
			pd_iep@34 {

				reg = <0x22>;
				clocks = <0x8 0xe1 0x8 0x1dd>;
				pm_qos = <0x60>;
			};
			pd_rga@33 {

				reg = <0x21>;
				clocks = <0x8 0xdc 0x8 0x1e5>;
				pm_qos = <0x61 0x62>;
			};
			pd_vcodec@31 {

				reg = <0x1f>;
				clocks = <0x8 0xeb 0x8 0x1ea>;
				pm_qos = <0x63>;
			};
			pd_vdu@32 {

				reg = <0x20>;
				clocks = <0x8 0xed 0x8 0x1ec>;
				pm_qos = <0x64 0x65>;
			};
			pd_gpu@35 {

				reg = <0x23>;
				clocks = <0x8 0xd0>;
				pm_qos = <0x66>;
			};
			pd_edp@25 {

				reg = <0x19>;
				clocks = <0x8 0x16c>;
			};
			pd_emmc@23 {

				reg = <0x17>;
				clocks = <0x8 0xf0>;
				pm_qos = <0x67>;
			};
			pd_gmac@22 {

				reg = <0x16>;
				clocks = <0x8 0xd5 0x8 0x166>;
				pm_qos = <0x68>;
			};
			pd_perihp@14 {

				reg = <0xe>;
				#address-cells = <0x1>;
				#size-cells = <0x0>;
				clocks = <0x8 0xc0>;
				pm_qos = <0x69 0x6a 0x6b 0x6c>;
				pd_sd@27 {

					reg = <0x1b>;
					clocks = <0x8 0x1ce 0x8 0x4c>;
					pm_qos = <0x6d>;
				};
			};
			pd_sdioaudio@28 {

				reg = <0x1c>;
				clocks = <0x8 0x1ee>;
				pm_qos = <0x6e>;
			};
			pd_usb3@24 {

				reg = <0x18>;
				clocks = <0x8 0xf4>;
				pm_qos = <0x6f 0x70>;
			};
			pd_vio@15 {

				reg = <0xf>;
				#address-cells = <0x1>;
				#size-cells = <0x0>;
				pd_hdcp@21 {

					reg = <0x15>;
					clocks = <0x8 0xde 0x8 0x1e7 0x8 0x172>;
					pm_qos = <0x71>;
				};
				pd_isp0@19 {

					reg = <0x13>;
					clocks = <0x8 0xe5 0x8 0x1df>;
					pm_qos = <0x72 0x73>;
				};
				pd_isp1@20 {

					reg = <0x14>;
					clocks = <0x8 0xe6 0x8 0x1e0>;
					pm_qos = <0x74 0x75>;
				};
				pd_tcpc0@RK3399_PD_TCPC0 {

					reg = <0x8>;
					clocks = <0x8 0x7e 0x8 0x7d>;
				};
				pd_tcpc1@RK3399_PD_TCPC1 {

					reg = <0x9>;
					clocks = <0x8 0x80 0x8 0x7f>;
				};
				pd_vo@16 {

					reg = <0x10>;
					#address-cells = <0x1>;
					#size-cells = <0x0>;
					pd_vopb@17 {

						reg = <0x11>;
						clocks = <0x8 0xd9 0x8 0x1d9>;
						pm_qos = <0x76 0x77>;
					};
					pd_vopl@18 {

						reg = <0x12>;
						clocks = <0x8 0xdb 0x8 0x1db>;
						pm_qos = <0x78>;
					};
				};
			};
		};
	};
	syscon@ff320000 {

		compatible = "rockchip,rk3399-pmugrf", "syscon", "simple-mfd";
		reg = <0x0 0xff320000 0x0 0x1000>;
		#address-cells = <0x1>;
		#size-cells = <0x1>;
		linux,phandle = <0x90>;
		phandle = <0x90>;
		io-domains {

			compatible = "rockchip,rk3399-pmu-io-voltage-domain";
			status = "okay";
			pmu1830-supply = <0x79>;
		};
		reboot-mode {

			compatible = "syscon-reboot-mode";
			offset = <0x300>;
			mode-bootloader = <0x5242c301>;
			mode-charge = <0x5242c30b>;
			mode-fastboot = <0x5242c309>;
			mode-loader = <0x5242c301>;
			mode-normal = <0x5242c300>;
			mode-recovery = <0x5242c303>;
			mode-ums = <0x5242c30c>;
		};
		pmu-pvtm {

			compatible = "rockchip,rk3399-pmu-pvtm";
			clocks = <0x31 0x7>;
			clock-names = "pmu";
			status = "disabled";
		};
	};
	spi@ff350000 {

		compatible = "rockchip,rk3399-spi", "rockchip,rk3066-spi";
		reg = <0x0 0xff350000 0x0 0x1000>;
		clocks = <0x31 0x3 0x31 0x1f>;
		clock-names = "spiclk", "apb_pclk";
		interrupts = <0x0 0x3c 0x4 0x0>;
		pinctrl-names = "default";
		pinctrl-0 = <0x7a 0x7b 0x7c 0x7d>;
		#address-cells = <0x1>;
		#size-cells = <0x0>;
		status = "disabled";
	};
	serial@ff370000 {

		compatible = "rockchip,rk3399-uart", "snps,dw-apb-uart";
		reg = <0x0 0xff370000 0x0 0x100>;
		clocks = <0x31 0x6 0x31 0x22>;
		clock-names = "baudclk", "apb_pclk";
		interrupts = <0x0 0x66 0x4 0x0>;
		reg-shift = <0x2>;
		reg-io-width = <0x4>;
		pinctrl-names = "default";
		pinctrl-0 = <0x7e>;
		status = "okay";
		assigned-clocks = <0x8 0xad>;
		assigned-clock-parents = <0x8 0x5>;
	};
	i2c@ff3d0000 {

		compatible = "rockchip,rk3399-i2c";
		reg = <0x0 0xff3d0000 0x0 0x1000>;
		clocks = <0x31 0xa 0x31 0x1c>;
		clock-names = "i2c", "pclk";
		interrupts = <0x0 0x38 0x4 0x0>;
		pinctrl-names = "default";
		pinctrl-0 = <0x7f>;
		#address-cells = <0x1>;
		#size-cells = <0x0>;
		status = "okay";
		i2c-scl-rising-time-ns = <0x258>;
		i2c-scl-falling-time-ns = <0x14>;
		clock-frequency = <0x61a80>;
		fusb30x@22 {

			compatible = "fairchild,fusb302";
			reg = <0x22>;
			pinctrl-names = "default";
			pinctrl-0 = <0x80>;
			int-n-gpios = <0x34 0x2 0x0>;
			vbus-5v-gpios = <0x81 0x1a 0x1>;
			status = "okay";
			linux,phandle = <0x29>;
			phandle = <0x29>;
		};
		lsm330_accel@1e {

			status = "okay";
			compatible = "lsm330_acc";
			pinctrl-names = "default";
			pinctrl-0 = <0x82>;
			reg = <0x1e>;
			irq-gpio = <0x34 0x16 0x1>;
			type = <0x2>;
			irq_enable = <0x0>;
			poll_delay_ms = <0x1e>;
			layout = <0x4>;
		};
		lsm330_gyro@6a {

			status = "okay";
			compatible = "lsm330_gyro";
			pinctrl-names = "default";
			pinctrl-0 = <0x83>;
			reg = <0x6a>;
			irq-gpio = <0x34 0x18 0x1>;
			type = <0x4>;
			irq_enable = <0x0>;
			poll_delay_ms = <0x1e>;
		};
		sensor@0f {

			status = "okay";
			compatible = "ak8963";
			pinctrl-names = "default";
			pinctrl-0 = <0x84>;
			reg = <0xf>;
			type = <0x3>;
			irq-gpio = <0x34 0x0 0x1>;
			irq_enable = <0x0>;
			poll_delay_ms = <0x1e>;
			layout = <0x3>;
		};
		sensor@10 {

			status = "okay";
			compatible = "capella,light_cm3218";
			pinctrl-names = "default";
			pinctrl-0 = <0x85>;
			reg = <0x10>;
			type = <0x5>;
			irq-gpio = <0x81 0x18 0x2>;
			irq_enable = <0x1>;
			poll_delay_ms = <0x1e>;
		};
	};
	i2c@ff3e0000 {

		compatible = "rockchip,rk3399-i2c";
		reg = <0x0 0xff3e0000 0x0 0x1000>;
		clocks = <0x31 0xb 0x31 0x1d>;
		clock-names = "i2c", "pclk";
		interrupts = <0x0 0x3a 0x4 0x0>;
		pinctrl-names = "default";
		pinctrl-0 = <0x86>;
		#address-cells = <0x1>;
		#size-cells = <0x0>;
		status = "disabled";
	};
	phy@e220 {

		compatible = "rockchip,rk3399-pcie-phy";
		#phy-cells = <0x0>;
		rockchip,grf = <0x17>;
		clocks = <0x8 0x8a>;
		clock-names = "refclk";
		resets = <0x8 0x87>;
		reset-names = "phy";
		status = "okay";
		linux,phandle = <0x89>;
		phandle = <0x89>;
	};
	pcie@f8000000 {

		compatible = "rockchip,rk3399-pcie";
		#address-cells = <0x3>;
		#size-cells = <0x2>;
		aspm-no-l0s;
		clocks = <0x8 0xc5 0x8 0xc4 0x8 0x147 0x8 0xa0>;
		clock-names = "aclk", "aclk-perf", "hclk", "pm";
		bus-range = <0x0 0x1>;
		max-link-speed = <0x1>;
		msi-map = <0x0 0x87 0x0 0x1000>;
		interrupts = <0x0 0x31 0x4 0x0 0x0 0x32 0x4 0x0 0x0 0x33 0x4 0x0>;
		interrupt-names = "sys", "legacy", "client";
		#interrupt-cells = <0x1>;
		interrupt-map-mask = <0x0 0x0 0x0 0x7>;
		interrupt-map = <0x0 0x0 0x0 0x1 0x88 0x0 0x0 0x0 0x0 0x2 0x88 0x1 0x0 0x0 0x0 0x3 0x88 0x2 0x0 0x0 0x0 0x4 0x88 0x3>;
		phys = <0x89>;
		phy-names = "pcie-phy";
		ranges = <0x82000000 0x0 0xfa000000 0x0 0xfa000000 0x0 0x600000 0x81000000 0x0 0xfa600000 0x0 0xfa600000 0x0 0x100000>;
		reg = <0x0 0xf8000000 0x0 0x2000000 0x0 0xfd000000 0x0 0x1000000>;
		reg-names = "axi-base", "apb-base";
		resets = <0x8 0x82 0x8 0x83 0x8 0x84 0x8 0x85 0x8 0x86 0x8 0x81 0x8 0x80>;
		reset-names = "core", "mgmt", "mgmt-sticky", "pipe", "pm", "pclk", "aclk";
		status = "okay";
		assigned-clocks = <0x8 0x8a>;
		assigned-clock-parents = <0x8 0xa7>;
		assigned-clock-rates = <0x5f5e100>;
		ep-gpios = <0x8a 0x4 0x0>;
		num-lanes = <0x4>;
		pinctrl-names = "default";
		pinctrl-0 = <0x8b>;
		interrupt-controller {

			interrupt-controller;
			#address-cells = <0x0>;
			#interrupt-cells = <0x1>;
			linux,phandle = <0x88>;
			phandle = <0x88>;
		};
	};
	pwm@ff420000 {

		compatible = "rockchip,rk3399-pwm", "rockchip,rk3288-pwm";
		reg = <0x0 0xff420000 0x0 0x10>;
		#pwm-cells = <0x3>;
		pinctrl-names = "default";
		pinctrl-0 = <0x8c>;
		clocks = <0x31 0x1e>;
		clock-names = "pwm";
		status = "okay";
		linux,phandle = <0xbe>;
		phandle = <0xbe>;
	};
	pwm@ff420010 {

		compatible = "rockchip,rk3399-pwm", "rockchip,rk3288-pwm";
		reg = <0x0 0xff420010 0x0 0x10>;
		#pwm-cells = <0x3>;
		pinctrl-names = "default";
		pinctrl-0 = <0x8d>;
		clocks = <0x31 0x1e>;
		clock-names = "pwm";
		status = "disabled";
	};
	pwm@ff420020 {

		compatible = "rockchip,rk3399-pwm", "rockchip,rk3288-pwm";
		reg = <0x0 0xff420020 0x0 0x10>;
		#pwm-cells = <0x3>;
		pinctrl-names = "default";
		pinctrl-0 = <0x8e>;
		clocks = <0x31 0x1e>;
		clock-names = "pwm";
		status = "okay";
		linux,phandle = <0xc2>;
		phandle = <0xc2>;
	};
	pwm@ff420030 {

		compatible = "rockchip,remotectl-pwm";
		reg = <0x0 0xff420030 0x0 0x10>;
		#pwm-cells = <0x3>;
		pinctrl-names = "default";
		pinctrl-0 = <0x8f>;
		clocks = <0x31 0x1e>;
		clock-names = "pwm";
		status = "okay";
		interrupts = <0x0 0x3d 0x4 0x0>;
		remote_pwm_id = <0x3>;
		handle_cpu_id = <0x0>;
		ir_key0 {

			rockchip,usercode = <0xff40>;
			rockchip,key_table = <0xb2 0x74 0xe5 0x66 0xbd 0x9e 0xba 0x8b 0xf4 0x67 0xf1 0x6c 0xef 0x69 0xee 0x6a 0xf2 0x1c 0xf0 0xe8 0xea 0x73 0xe3 0x72 0xbc 0x71 0xfe 0x2 0xfd 0x3 0xfc 0x4 0xfb 0x5 0xfa 0x6 0xf9 0x7 0xf8 0x8 0xf7 0x9 0xb6 0xa 0xff 0xb 0xed 0xe 0xaf 0x74 0x8b 0x73 0xb9 0x72>;
		};
	};
	dfi@ff630000 {

		reg = <0x0 0xff630000 0x0 0x4000>;
		compatible = "rockchip,rk3399-dfi";
		rockchip,pmu = <0x90>;
		clocks = <0x8 0x179>;
		clock-names = "pclk_ddr_mon";
		status = "disabled";
		linux,phandle = <0x91>;
		phandle = <0x91>;
	};
	dmc {

		compatible = "rockchip,rk3399-dmc";
		devfreq-events = <0x91>;
		interrupts = <0x0 0x1 0x4 0x0>;
		clocks = <0x8 0xaa>;
		clock-names = "dmc_clk";
		ddr_timing = <0x92>;
		status = "disabled";
		operating-points-v2 = <0x93>;
	};
	vpu_service@ff650000 {

		compatible = "rockchip,vpu_service";
		rockchip,grf = <0x17>;
		iommus = <0x94>;
		iommu_enabled = <0x1>;
		reg = <0x0 0xff650000 0x0 0x800>;
		interrupts = <0x0 0x71 0x4 0x0 0x0 0x72 0x4 0x0>;
		interrupt-names = "irq_dec", "irq_enc";
		clocks = <0x8 0xeb 0x8 0x1ea>;
		clock-names = "aclk_vcodec", "hclk_vcodec";
		resets = <0x8 0x53 0x8 0x51>;
		reset-names = "video_h", "video_a";
		power-domains = <0x18 0x1f>;
		dev_mode = <0x0>;
		allocator = <0x1>;
		status = "okay";
	};
	iommu@ff650800 {

		compatible = "rockchip,iommu";
		reg = <0x0 0xff650800 0x0 0x40>;
		interrupts = <0x0 0x73 0x4 0x0>;
		interrupt-names = "vpu_mmu";
		clocks = <0x8 0xeb 0x8 0x1ea>;
		clock-names = "aclk", "hclk";
		power-domains = <0x18 0x1f>;
		#iommu-cells = <0x0>;
		linux,phandle = <0x94>;
		phandle = <0x94>;
	};
	rkvdec@ff660000 {

		compatible = "rockchip,rkvdec";
		rockchip,grf = <0x17>;
		iommus = <0x95>;
		iommu_enabled = <0x1>;
		reg = <0x0 0xff660000 0x0 0x400>;
		interrupts = <0x0 0x74 0x4 0x0>;
		interrupt-names = "irq_dec";
		clocks = <0x8 0xed 0x8 0x1ec 0x8 0x9f 0x8 0x9e>;
		clock-names = "aclk_vcodec", "hclk_vcodec", "clk_cabac", "clk_core";
		resets = <0x8 0x5b 0x8 0x59>;
		reset-names = "video_h", "video_a";
		power-domains = <0x18 0x20>;
		dev_mode = <0x2>;
		allocator = <0x1>;
		status = "okay";
	};
	iommu@ff660480 {

		compatible = "rockchip,iommu";
		reg = <0x0 0xff660480 0x0 0x40 0x0 0xff6604c0 0x0 0x40>;
		interrupts = <0x0 0x75 0x4 0x0>;
		interrupt-names = "vdec_mmu";
		clocks = <0x8 0xed 0x8 0x1ec>;
		clock-names = "aclk", "hclk";
		power-domains = <0x18 0x20>;
		#iommu-cells = <0x0>;
		linux,phandle = <0x95>;
		phandle = <0x95>;
	};
	rga@ff680000 {

		compatible = "rockchip,rga2";
		reg = <0x0 0xff680000 0x0 0x1000>;
		interrupts = <0x0 0x37 0x4 0x0>;
		interrupt-names = "rga";
		clocks = <0x8 0xdc 0x8 0x1e5 0x8 0x6d>;
		clock-names = "aclk_rga", "hclk_rga", "clk_rga";
		resets = <0x8 0x6a 0x8 0x67 0x8 0x69>;
		reset-names = "core", "axi", "ahb";
		power-domains = <0x18 0x21>;
		status = "okay";
		dev_mode = <0x1>;
		dma-coherent;
	};
	efuse@ff690000 {

		compatible = "rockchip,rk3399-efuse";
		reg = <0x0 0xff690000 0x0 0x80>;
		#address-cells = <0x1>;
		#size-cells = <0x1>;
		clocks = <0x8 0x17d>;
		clock-names = "pclk_efuse";
		cpul-leakage {

			reg = <0x1a 0x1>;
			linux,phandle = <0x13>;
			phandle = <0x13>;
		};
		cpub-leakage {

			reg = <0x17 0x1>;
			linux,phandle = <0x14>;
			phandle = <0x14>;
		};
		gpu-leakage {

			reg = <0x18 0x1>;
		};
		center-leakage {

			reg = <0x19 0x1>;
		};
		logic-leakage {

			reg = <0x1b 0x1>;
		};
		wafer-info {

			reg = <0x1c 0x1>;
		};
	};
	pmu-clock-controller@ff750000 {

		compatible = "rockchip,rk3399-pmucru";
		reg = <0x0 0xff750000 0x0 0x1000>;
		#clock-cells = <0x1>;
		#reset-cells = <0x1>;
		assigned-clocks = <0x31 0x1>;
		assigned-clock-rates = <0x284af100>;
		linux,phandle = <0x31>;
		phandle = <0x31>;
	};
	clock-controller@ff760000 {

		compatible = "rockchip,rk3399-cru";
		reg = <0x0 0xff760000 0x0 0x1000>;
		#clock-cells = <0x1>;
		#reset-cells = <0x1>;
		assigned-clocks = <0x8 0xc0 0x8 0xc2 0x8 0x1c2 0x8 0xd9 0x8 0xdb 0x8 0x4c 0x8 0xf0 0x8 0xcd 0x8 0x1cd 0x8 0x9f 0x8 0x9e 0x8 0xf4 0x8 0xbe 0x8 0xc9 0x8 0x186 0x8 0xd5 0x8 0x88 0x8 0x87 0x8 0x8 0x8 0x9 0x8 0x6 0x8 0xd0 0x8 0x5 0x8 0xc0 0x8 0x1c0 0x8 0x140 0x8 0xc2 0x8 0x1c1 0x8 0x142 0x8 0x1c2 0x8 0x143 0x8 0xd9 0x8 0x1d9 0x8 0xdb 0x8 0x1db 0x8 0x41 0x8 0x42 0x8 0x43 0x8 0x44 0x8 0x45 0x8 0x46 0x8 0x47 0x8 0x48 0x8 0x49 0x8 0x4a 0x8 0x4b 0x8 0xfa 0x8 0xe5 0x8 0xe6 0x8 0x6b 0x8 0x6c 0x8 0x16a 0x8 0xde 0x8 0xe3 0x8 0x1cd 0x8 0x85 0x8 0x86 0x8 0x4e 0x8 0xf0 0x8 0xcd 0x8 0xe1 0x8 0xdc 0x8 0x6d 0x8 0xed 0x8 0xeb 0x8 0x178 0x8 0xd5 0x8 0x9f 0x8 0x9e 0x8 0xf4 0x8 0xbe 0x8 0xc9 0x8 0x186 0x8 0x88 0x8 0x87>;
		assigned-clock-rates = <0x47868c0 0x2faf080 0x2faf080 0xbebc200 0xbebc200 0x2faf080 0x2faf080 0x5f5e100 0x2faf080 0x8f0d180 0x8f0d180 0x8f0d180 0x2faf080 0x8f0d180 0x2faf080 0x5f5e100 0x47868c0 0x47868c0 0x30a32c00 0x30a32c00 0x23c34600 0xbebc200 0x2faf0800 0x8f0d180 0x47868c0 0x23c3460 0x5f5e100 0x5f5e100 0x2faf080 0x5f5e100 0x2faf080 0x17d78400 0xbebc200 0x17d78400 0xbebc200 0x5f5e100 0x5f5e100 0x5f5e100 0x5f5e100 0x5f5e100 0x5f5e100 0x2faf080 0x2faf080 0x2faf080 0x2faf080 0x2faf080 0xbebc200 0x17d78400 0x17d78400 0x5f5e100 0x5f5e100 0x5f5e100 0x17d78400 0x17d78400 0xbebc200 0x5f5e100 0xbebc200 0xbebc200 0x5f5e100 0x17d78400 0x17d78400 0x17d78400 0x17d78400 0x11e1a300 0x17d78400 0xbebc200 0x17d78400 0x11e1a300 0x11e1a300 0x11e1a300 0x11e1a300 0x11e1a300 0x5f5e100 0x8f0d180 0x8f0d180>;
		linux,phandle = <0x8>;
		phandle = <0x8>;
	};
	syscon@ff770000 {

		compatible = "rockchip,rk3399-grf", "syscon", "simple-mfd";
		reg = <0x0 0xff770000 0x0 0x10000>;
		#address-cells = <0x1>;
		#size-cells = <0x1>;
		linux,phandle = <0x17>;
		phandle = <0x17>;
		io-domains {

			compatible = "rockchip,rk3399-io-voltage-domain";
			status = "okay";
			bt656-supply = <0x79>;
			audio-supply = <0x96>;
			sdmmc-supply = <0x21>;
			gpio1830-supply = <0x97>;
		};
		phy@f780 {

			compatible = "rockchip,rk3399-emmc-phy";
			reg = <0xf780 0x24>;
			clocks = <0x98>;
			clock-names = "emmcclk";
			#phy-cells = <0x0>;
			status = "okay";
			linux,phandle = <0x26>;
			phandle = <0x26>;
		};
		usb2-phy@e450 {

			compatible = "rockchip,rk3399-usb2phy";
			reg = <0xe450 0x10>;
			clocks = <0x8 0x7b>;
			clock-names = "phyclk";
			#clock-cells = <0x0>;
			clock-output-names = "clk_usbphy0_480m";
			status = "okay";
			extcon = <0x29>;
			otg-port {

				#phy-cells = <0x0>;
				interrupts = <0x0 0x67 0x4 0x0 0x0 0x68 0x4 0x0 0x0 0x6a 0x4 0x0>;
				interrupt-names = "otg-bvalid", "otg-id", "linestate";
				status = "okay";
				linux,phandle = <0x2a>;
				phandle = <0x2a>;
			};
			host-port {

				#phy-cells = <0x0>;
				interrupts = <0x0 0x1b 0x4 0x0>;
				interrupt-names = "linestate";
				status = "okay";
				phy-supply = <0x99>;
				linux,phandle = <0x27>;
				phandle = <0x27>;
			};
		};
		usb2-phy@e460 {

			compatible = "rockchip,rk3399-usb2phy";
			reg = <0xe460 0x10>;
			clocks = <0x8 0x7c>;
			clock-names = "phyclk";
			#clock-cells = <0x0>;
			clock-output-names = "clk_usbphy1_480m";
			status = "okay";
			otg-port {

				#phy-cells = <0x0>;
				interrupts = <0x0 0x6c 0x4 0x0 0x0 0x6d 0x4 0x0 0x0 0x6f 0x4 0x0>;
				interrupt-names = "otg-bvalid", "otg-id", "linestate";
				status = "okay";
				linux,phandle = <0x2c>;
				phandle = <0x2c>;
			};
			host-port {

				#phy-cells = <0x0>;
				interrupts = <0x0 0x1f 0x4 0x0>;
				interrupt-names = "linestate";
				status = "okay";
				phy-supply = <0x99>;
				linux,phandle = <0x28>;
				phandle = <0x28>;
			};
		};
		pvtm {

			compatible = "rockchip,rk3399-pvtm";
			clocks = <0x8 0x73 0x8 0x74 0x8 0x75 0x8 0x76>;
			clock-names = "core_l", "core_b", "gpu", "ddr";
			status = "disabled";
		};
	};
	phy@ff7c0000 {

		compatible = "rockchip,rk3399-typec-phy";
		reg = <0x0 0xff7c0000 0x0 0x40000>;
		rockchip,grf = <0x17>;
		#phy-cells = <0x1>;
		clocks = <0x8 0x7e 0x8 0x7d>;
		clock-names = "tcpdcore", "tcpdphy-ref";
		assigned-clocks = <0x8 0x7e>;
		assigned-clock-rates = <0x2faf080>;
		power-domains = <0x18 0x8>;
		resets = <0x8 0x95 0x8 0x94 0x8 0x14c>;
		reset-names = "uphy", "uphy-pipe", "uphy-tcphy";
		rockchip,typec-conn-dir = <0xe580 0x0 0x10>;
		rockchip,usb3tousb2-en = <0xe580 0x3 0x13>;
		rockchip,usb3-host-disable = <0x2434 0x0 0x10>;
		rockchip,usb3-host-port = <0x2434 0xc 0x1c>;
		rockchip,external-psm = <0xe588 0xe 0x1e>;
		rockchip,pipe-status = <0xe5c0 0x0 0x0>;
		rockchip,uphy-dp-sel = <0x6268 0x13 0x13>;
		status = "okay";
		extcon = <0x29>;
		dp-port {

			#phy-cells = <0x0>;
			linux,phandle = <0x2e>;
			phandle = <0x2e>;
		};
		usb3-port {

			#phy-cells = <0x0>;
			linux,phandle = <0x2b>;
			phandle = <0x2b>;
		};
	};
	phy@ff800000 {

		compatible = "rockchip,rk3399-typec-phy";
		reg = <0x0 0xff800000 0x0 0x40000>;
		rockchip,grf = <0x17>;
		#phy-cells = <0x1>;
		clocks = <0x8 0x80 0x8 0x7f>;
		clock-names = "tcpdcore", "tcpdphy-ref";
		assigned-clocks = <0x8 0x80>;
		assigned-clock-rates = <0x2faf080>;
		power-domains = <0x18 0x9>;
		resets = <0x8 0x9d 0x8 0x9c 0x8 0x14d>;
		reset-names = "uphy", "uphy-pipe", "uphy-tcphy";
		rockchip,typec-conn-dir = <0xe58c 0x0 0x10>;
		rockchip,usb3tousb2-en = <0xe58c 0x3 0x13>;
		rockchip,usb3-host-disable = <0x2444 0x0 0x10>;
		rockchip,usb3-host-port = <0x2444 0xc 0x1c>;
		rockchip,external-psm = <0xe594 0xe 0x1e>;
		rockchip,pipe-status = <0xe5c0 0x10 0x10>;
		rockchip,uphy-dp-sel = <0x6268 0x3 0x13>;
		status = "okay";
		dp-port {

			#phy-cells = <0x0>;
		};
		usb3-port {

			#phy-cells = <0x0>;
			linux,phandle = <0x2d>;
			phandle = <0x2d>;
		};
	};
	watchdog@ff848000 {

		compatible = "snps,dw-wdt";
		reg = <0x0 0xff848000 0x0 0x100>;
		clocks = <0x8 0x17c>;
		interrupts = <0x0 0x78 0x4 0x0>;
	};
	rktimer@ff850000 {

		compatible = "rockchip,rk3399-timer";
		reg = <0x0 0xff850000 0x0 0x1000>;
		interrupts = <0x0 0x51 0x4 0x0>;
		clocks = <0x8 0x168 0x8 0x5a>;
		clock-names = "pclk", "timer";
	};
	spdif@ff870000 {

		compatible = "rockchip,rk3399-spdif";
		reg = <0x0 0xff870000 0x0 0x1000>;
		interrupts = <0x0 0x42 0x4 0x0>;
		dmas = <0x9a 0x7>;
		dma-names = "tx";
		clock-names = "mclk", "hclk";
		clocks = <0x8 0x55 0x8 0x1d7>;
		pinctrl-names = "default";
		pinctrl-0 = <0x9b>;
		power-domains = <0x18 0x1c>;
		status = "okay";
		i2c-scl-rising-time-ns = <0x1c2>;
		i2c-scl-falling-time-ns = <0xf>;
		#sound-dai-cells = <0x0>;
		assigned-clocks = <0x8 0xb1>;
		assigned-clock-parents = <0x8 0x5>;
		linux,phandle = <0xc5>;
		phandle = <0xc5>;
	};
	i2s@ff880000 {

		compatible = "rockchip,rk3399-i2s", "rockchip,rk3066-i2s";
		reg = <0x0 0xff880000 0x0 0x1000>;
		rockchip,grf = <0x17>;
		interrupts = <0x0 0x27 0x4 0x0>;
		dmas = <0x9a 0x0 0x9a 0x1>;
		dma-names = "tx", "rx";
		clock-names = "i2s_clk", "i2s_hclk";
		clocks = <0x8 0x56 0x8 0x1d4>;
		pinctrl-names = "default";
		pinctrl-0 = <0x9c>;
		power-domains = <0x18 0x1c>;
		status = "okay";
		rockchip,i2s-broken-burst-len;
		rockchip,playback-channels = <0x8>;
		rockchip,capture-channels = <0x8>;
		#sound-dai-cells = <0x0>;
		assigned-clocks = <0x8 0xae>;
		assigned-clock-parents = <0x8 0x5>;
		linux,phandle = <0xc3>;
		phandle = <0xc3>;
	};
	i2s@ff890000 {

		compatible = "rockchip,rk3399-i2s", "rockchip,rk3066-i2s";
		reg = <0x0 0xff890000 0x0 0x1000>;
		interrupts = <0x0 0x28 0x4 0x0>;
		dmas = <0x9a 0x2 0x9a 0x3>;
		dma-names = "tx", "rx";
		clock-names = "i2s_clk", "i2s_hclk";
		clocks = <0x8 0x57 0x8 0x1d5>;
		pinctrl-names = "default";
		pinctrl-0 = <0x9d>;
		power-domains = <0x18 0x1c>;
		status = "disabled";
		assigned-clocks = <0x8 0xaf>;
		assigned-clock-parents = <0x8 0x5>;
	};
	i2s@ff8a0000 {

		compatible = "rockchip,rk3399-i2s", "rockchip,rk3066-i2s";
		reg = <0x0 0xff8a0000 0x0 0x1000>;
		interrupts = <0x0 0x29 0x4 0x0>;
		dmas = <0x9a 0x4 0x9a 0x5>;
		dma-names = "tx", "rx";
		clock-names = "i2s_clk", "i2s_hclk";
		clocks = <0x8 0x58 0x8 0x1d6>;
		power-domains = <0x18 0x1c>;
		status = "okay";
		#sound-dai-cells = <0x0>;
		assigned-clocks = <0x8 0xb0>;
		assigned-clock-parents = <0x8 0x5>;
		linux,phandle = <0xc7>;
		phandle = <0xc7>;
	};
	gpu@ff9a0000 {

		compatible = "arm,malit860", "arm,malit86x", "arm,malit8xx", "arm,mali-midgard";
		reg = <0x0 0xff9a0000 0x0 0x10000>;
		interrupts = <0x0 0x13 0x4 0x0 0x0 0x14 0x4 0x0 0x0 0x15 0x4 0x0>;
		interrupt-names = "GPU", "JOB", "MMU";
		clocks = <0x8 0xd0>;
		clock-names = "clk_mali";
		#cooling-cells = <0x2>;
		power-domains = <0x18 0x23>;
		power-off-delay-ms = <0xc8>;
		status = "okay";
		operating-points-v2 = <0x9e>;
		mali-supply = <0x9f>;
		linux,phandle = <0x5d>;
		phandle = <0x5d>;
		power_model {

			compatible = "arm,mali-simple-power-model";
			voltage = <0x384>;
			frequency = <0x1f4>;
			static-power = <0x12c>;
			dynamic-power = <0x18c>;
			ts = <0x7d00 0x125c 0xffffffb0 0x2>;
			thermal-zone = "gpu-thermal";
		};
	};
	vop@ff8f0000 {

		compatible = "rockchip,rk3399-vop-lit";
		reg = <0x0 0xff8f0000 0x0 0x3efc>;
		interrupts = <0x0 0x77 0x4 0x0>;
		clocks = <0x8 0xdb 0x8 0xb5 0x8 0x1db>;
		clock-names = "aclk_vop", "dclk_vop", "hclk_vop";
		resets = <0x8 0x113 0x8 0x117 0x8 0x119>;
		reset-names = "axi", "ahb", "dclk";
		power-domains = <0x18 0x12>;
		iommus = <0xa0>;
		status = "okay";
		assigned-clocks = <0x8 0xb7>;
		assigned-clock-parents = <0x8 0x7>;
		port {

			#address-cells = <0x1>;
			#size-cells = <0x0>;
			linux,phandle = <0xb7>;
			phandle = <0xb7>;
			endpoint@0 {

				reg = <0x0>;
				remote-endpoint = <0xa1>;
				linux,phandle = <0xb0>;
				phandle = <0xb0>;
			};
			endpoint@1 {

				reg = <0x1>;
				remote-endpoint = <0xa2>;
				linux,phandle = <0xb5>;
				phandle = <0xb5>;
			};
			endpoint@2 {

				reg = <0x2>;
				remote-endpoint = <0xa3>;
				linux,phandle = <0xae>;
				phandle = <0xae>;
			};
			endpoint@3 {

				reg = <0x3>;
				remote-endpoint = <0xa4>;
				linux,phandle = <0x30>;
				phandle = <0x30>;
			};
		};
	};
	voppwm@ff8f01a0 {

		compatible = "rockchip,vop-pwm";
		reg = <0x0 0xff8f01a0 0x0 0x10>;
		#pwm-cells = <0x3>;
		pinctrl-names = "default";
		pinctrl-0 = <0xa5>;
		clocks = <0x8 0x6c>;
		clock-names = "pwm";
		status = "disabled";
	};
	iommu@ff8f3f00 {

		compatible = "rockchip,iommu";
		reg = <0x0 0xff8f3f00 0x0 0x100>;
		interrupts = <0x0 0x77 0x4 0x0>;
		interrupt-names = "vopl_mmu";
		clocks = <0x8 0xdb 0x8 0x1db>;
		clock-names = "aclk", "hclk";
		power-domains = <0x18 0x12>;
		#iommu-cells = <0x0>;
		status = "okay";
		linux,phandle = <0xa0>;
		phandle = <0xa0>;
	};
	vop@ff900000 {

		compatible = "rockchip,rk3399-vop-big";
		reg = <0x0 0xff900000 0x0 0x3efc>;
		interrupts = <0x0 0x76 0x4 0x0>;
		clocks = <0x8 0xd9 0x8 0xb4 0x8 0x1d9>;
		clock-names = "aclk_vop", "dclk_vop", "hclk_vop";
		resets = <0x8 0x112 0x8 0x116 0x8 0x118>;
		reset-names = "axi", "ahb", "dclk";
		power-domains = <0x18 0x11>;
		iommus = <0xa6>;
		status = "okay";
		assigned-clocks = <0x8 0xb6>;
		assigned-clock-parents = <0x8 0x4>;
		port {

			#address-cells = <0x1>;
			#size-cells = <0x0>;
			linux,phandle = <0xb6>;
			phandle = <0xb6>;
			endpoint@0 {

				reg = <0x0>;
				remote-endpoint = <0xa7>;
				linux,phandle = <0xb4>;
				phandle = <0xb4>;
			};
			endpoint@1 {

				reg = <0x1>;
				remote-endpoint = <0xa8>;
				linux,phandle = <0xaf>;
				phandle = <0xaf>;
			};
			endpoint@2 {

				reg = <0x2>;
				remote-endpoint = <0xa9>;
				linux,phandle = <0xad>;
				phandle = <0xad>;
			};
			endpoint@3 {

				reg = <0x3>;
				remote-endpoint = <0xaa>;
				linux,phandle = <0x2f>;
				phandle = <0x2f>;
			};
		};
	};
	voppwm@ff9001a0 {

		compatible = "rockchip,vop-pwm";
		reg = <0x0 0xff9001a0 0x0 0x10>;
		#pwm-cells = <0x3>;
		pinctrl-names = "default";
		pinctrl-0 = <0xab>;
		clocks = <0x8 0x6b>;
		clock-names = "pwm";
		status = "disabled";
	};
	iommu@ff903f00 {

		compatible = "rockchip,iommu";
		reg = <0x0 0xff903f00 0x0 0x100>;
		interrupts = <0x0 0x76 0x4 0x0>;
		interrupt-names = "vopb_mmu";
		clocks = <0x8 0xd9 0x8 0x1d9>;
		clock-names = "aclk", "hclk";
		power-domains = <0x18 0x11>;
		#iommu-cells = <0x0>;
		status = "okay";
		linux,phandle = <0xa6>;
		phandle = <0xa6>;
	};
	iommu@ff914000 {

		compatible = "rockchip,iommu";
		reg = <0x0 0xff914000 0x0 0x100 0x0 0xff915000 0x0 0x100>;
		interrupts = <0x0 0x2b 0x4 0x0>;
		interrupt-names = "isp0_mmu";
		#iommu-cells = <0x0>;
		clocks = <0x8 0xe7 0x8 0x1e1>;
		clock-names = "aclk", "hclk";
		power-domains = <0x18 0x13>;
		rk_iommu,disable_reset_quirk;
		status = "okay";
		linux,phandle = <0xda>;
		phandle = <0xda>;
	};
	iommu@ff924000 {

		compatible = "rockchip,iommu";
		reg = <0x0 0xff924000 0x0 0x100 0x0 0xff925000 0x0 0x100>;
		interrupts = <0x0 0x2c 0x4 0x0>;
		interrupt-names = "isp1_mmu";
		#iommu-cells = <0x0>;
		clocks = <0x8 0xe8 0x8 0x1e2>;
		clock-names = "aclk", "hclk";
		power-domains = <0x18 0x14>;
		rk_iommu,disable_reset_quirk;
		status = "okay";
		linux,phandle = <0xdb>;
		phandle = <0xdb>;
	};
	hdmi@ff940000 {

		compatible = "rockchip,rk3399-dw-hdmi";
		reg = <0x0 0xff940000 0x0 0x20000>;
		reg-io-width = <0x4>;
		rockchip,grf = <0x17>;
		pinctrl-names = "default";
		pinctrl-0 = <0xac>;
		power-domains = <0x18 0x15>;
		interrupts = <0x0 0x17 0x4 0x0>;
		clocks = <0x8 0x174 0x8 0x71 0x8 0x7 0x8 0x16f>;
		clock-names = "iahb", "isfr", "vpll", "grf";
		status = "okay";
		#address-cells = <0x1>;
		#size-cells = <0x0>;
		#sound-dai-cells = <0x0>;
		linux,phandle = <0xc8>;
		phandle = <0xc8>;
		ports {

			port {

				#address-cells = <0x1>;
				#size-cells = <0x0>;
				endpoint@0 {

					reg = <0x0>;
					remote-endpoint = <0xad>;
					status = "disabled";
					linux,phandle = <0xa9>;
					phandle = <0xa9>;
				};
				endpoint@1 {

					reg = <0x1>;
					remote-endpoint = <0xae>;
					linux,phandle = <0xa3>;
					phandle = <0xa3>;
				};
			};
		};
	};
	mipi@ff960000 {

		compatible = "rockchip,rk3399-mipi-dsi", "snps,dw-mipi-dsi";
		reg = <0x0 0xff960000 0x0 0x8000>;
		interrupts = <0x0 0x2d 0x4 0x0>;
		clocks = <0x8 0x77 0x8 0x170 0x8 0xa3>;
		clock-names = "ref", "pclk", "phy_cfg";
		power-domains = <0x18 0xf>;
		rockchip,grf = <0x17>;
		#address-cells = <0x1>;
		#size-cells = <0x0>;
		status = "okay";
		ports {

			#address-cells = <0x1>;
			#size-cells = <0x0>;
			reg = <0x1>;
			port {

				#address-cells = <0x1>;
				#size-cells = <0x0>;
				endpoint@0 {

					reg = <0x0>;
					remote-endpoint = <0xaf>;
					linux,phandle = <0xa8>;
					phandle = <0xa8>;
				};
				endpoint@1 {

					reg = <0x1>;
					remote-endpoint = <0xb0>;
					status = "disabled";
					linux,phandle = <0xa1>;
					phandle = <0xa1>;
				};
			};
		};
		panel {

			compatible = "simple-panel-dsi";
			reg = <0x0>;
			backlight = <0xb1>;
			enable-gpios = <0x34 0xd 0x0>;
			dsi,flags = <0x7>;
			dsi,format = <0x0>;
			dsi,lanes = <0x4>;
			status = "okay";
			display-timings {

				native-mode = <0xb2>;
				timing0 {

					clock-frequency = <0x42c1d80>;
					hactive = <0x400>;
					vactive = <0x258>;
					hback-porch = <0x50>;
					hfront-porch = <0x50>;
					vback-porch = <0x14>;
					vfront-porch = <0xc>;
					hsync-len = <0x2>;
					vsync-len = <0x3>;
					hsync-active = <0x0>;
					vsync-active = <0x0>;
					de-active = <0x0>;
					pixelclk-active = <0x0>;
					linux,phandle = <0xb2>;
					phandle = <0xb2>;
				};
			};
		};
	};
	edp@ff970000 {

		compatible = "rockchip,rk3399-edp";
		reg = <0x0 0xff970000 0x0 0x8000>;
		interrupts = <0x0 0xa 0x4 0x0>;
		clocks = <0x8 0x16a 0x8 0x16c>;
		clock-names = "dp", "pclk";
		power-domains = <0x18 0x19>;
		resets = <0x8 0x11d>;
		reset-names = "dp";
		rockchip,grf = <0x17>;
		status = "disabled";
		pinctrl-names = "default";
		pinctrl-0 = <0xb3>;
		ports {

			#address-cells = <0x1>;
			#size-cells = <0x0>;
			port@0 {

				reg = <0x0>;
				#address-cells = <0x1>;
				#size-cells = <0x0>;
				endpoint@0 {

					reg = <0x0>;
					remote-endpoint = <0xb4>;
					linux,phandle = <0xa7>;
					phandle = <0xa7>;
				};
				endpoint@1 {

					reg = <0x1>;
					remote-endpoint = <0xb5>;
					linux,phandle = <0xa2>;
					phandle = <0xa2>;
				};
			};
		};
	};
	display-subsystem {

		compatible = "rockchip,display-subsystem";
		ports = <0xb6 0xb7>;
		status = "okay";
		memory-region = <0xb8>;
		route {

			route-hdmi {

				status = "disabled";
				logo,uboot = "logo.bmp";
				logo,kernel = "logo_kernel.bmp";
				logo,mode = "center";
				charge_logo,mode = "center";
				connect = <0xad>;
			};
			route-mipi {

				status = "okay";
				logo,uboot = "logo.bmp";
				logo,kernel = "logo_kernel.bmp";
				logo,mode = "center";
				charge_logo,mode = "center";
				connect = <0xaf>;
			};
			route-edp {

				status = "disabled";
				logo,uboot = "logo.bmp";
				logo,kernel = "logo_kernel.bmp";
				logo,mode = "center";
				charge_logo,mode = "center";
				connect = <0xb4>;
			};
		};
	};
	pinctrl {

		compatible = "rockchip,rk3399-pinctrl";
		rockchip,grf = <0x17>;
		rockchip,pmu = <0x90>;
		#address-cells = <0x2>;
		#size-cells = <0x2>;
		ranges;
		gpio0@ff720000 {

			compatible = "rockchip,gpio-bank";
			reg = <0x0 0xff720000 0x0 0x100>;
			clocks = <0x31 0x17>;
			interrupts = <0x0 0xe 0x4 0x0>;
			gpio-controller;
			#gpio-cells = <0x2>;
			interrupt-controller;
			#interrupt-cells = <0x2>;
			linux,phandle = <0x3a>;
			phandle = <0x3a>;
		};
		gpio1@ff730000 {

			compatible = "rockchip,gpio-bank";
			reg = <0x0 0xff730000 0x0 0x100>;
			clocks = <0x31 0x18>;
			interrupts = <0x0 0xf 0x4 0x0>;
			gpio-controller;
			#gpio-cells = <0x2>;
			interrupt-controller;
			#interrupt-cells = <0x2>;
			linux,phandle = <0x34>;
			phandle = <0x34>;
		};
		gpio2@ff780000 {

			compatible = "rockchip,gpio-bank";
			reg = <0x0 0xff780000 0x0 0x100>;
			clocks = <0x8 0x150>;
			interrupts = <0x0 0x10 0x4 0x0>;
			gpio-controller;
			#gpio-cells = <0x2>;
			interrupt-controller;
			#interrupt-cells = <0x2>;
			linux,phandle = <0x8a>;
			phandle = <0x8a>;
		};
		gpio3@ff788000 {

			compatible = "rockchip,gpio-bank";
			reg = <0x0 0xff788000 0x0 0x100>;
			clocks = <0x8 0x151>;
			interrupts = <0x0 0x11 0x4 0x0>;
			gpio-controller;
			#gpio-cells = <0x2>;
			interrupt-controller;
			#interrupt-cells = <0x2>;
			linux,phandle = <0x1a>;
			phandle = <0x1a>;
		};
		gpio4@ff790000 {

			compatible = "rockchip,gpio-bank";
			reg = <0x0 0xff790000 0x0 0x100>;
			clocks = <0x8 0x152>;
			interrupts = <0x0 0x12 0x4 0x0>;
			gpio-controller;
			#gpio-cells = <0x2>;
			interrupt-controller;
			#interrupt-cells = <0x2>;
			linux,phandle = <0x81>;
			phandle = <0x81>;
		};
		pcfg-pull-up {

			bias-pull-up;
			linux,phandle = <0xb9>;
			phandle = <0xb9>;
		};
		pcfg-pull-down {

			bias-pull-down;
			linux,phandle = <0xbd>;
			phandle = <0xbd>;
		};
		pcfg-pull-none {

			bias-disable;
			linux,phandle = <0xbb>;
			phandle = <0xbb>;
		};
		pcfg-pull-up-20ma {

			bias-pull-up;
			drive-strength = <0x14>;
		};
		pcfg-pull-none-20ma {

			bias-disable;
			drive-strength = <0x14>;
		};
		pcfg-pull-none-18ma {

			bias-disable;
			drive-strength = <0x12>;
		};
		pcfg-pull-none-12ma {

			bias-disable;
			drive-strength = <0xc>;
			linux,phandle = <0xbc>;
			phandle = <0xbc>;
		};
		pcfg-pull-up-8ma {

			bias-pull-up;
			drive-strength = <0x8>;
		};
		pcfg-pull-down-4ma {

			bias-pull-down;
			drive-strength = <0x4>;
		};
		pcfg-pull-up-2ma {

			bias-pull-up;
			drive-strength = <0x2>;
		};
		pcfg-pull-down-12ma {

			bias-pull-down;
			drive-strength = <0xc>;
		};
		pcfg-pull-none-13ma {

			bias-disable;
			drive-strength = <0xd>;
			linux,phandle = <0xba>;
			phandle = <0xba>;
		};
		pcfg-output-high {

			output-high;
		};
		pcfg-output-low {

			output-low;
		};
		pcfg-input {

			input-enable;
		};
		emmc {

			emmc-pwr {

				rockchip,pins = <0x0 0x5 0x1 0xb9>;
			};
		};
		gmac {

			rgmii-pins {

				rockchip,pins = <0x3 0x11 0x1 0xba 0x3 0xe 0x1 0xbb 0x3 0xd 0x1 0xbb 0x3 0xc 0x1 0xba 0x3 0xb 0x1 0xbb 0x3 0x9 0x1 0xbb 0x3 0x8 0x1 0xbb 0x3 0x7 0x1 0xbb 0x3 0x6 0x1 0xbb 0x3 0x5 0x1 0xba 0x3 0x4 0x1 0xba 0x3 0x3 0x1 0xbb 0x3 0x2 0x1 0xbb 0x3 0x1 0x1 0xba 0x3 0x0 0x1 0xba>;
				linux,phandle = <0x1c>;
				phandle = <0x1c>;
			};
			rmii-pins {

				rockchip,pins = <0x3 0xd 0x1 0xbb 0x3 0xc 0x1 0xba 0x3 0xb 0x1 0xbb 0x3 0xa 0x1 0xbb 0x3 0x9 0x1 0xbb 0x3 0x8 0x1 0xbb 0x3 0x7 0x1 0xbb 0x3 0x6 0x1 0xbb 0x3 0x5 0x1 0xba 0x3 0x4 0x1 0xba>;
			};
		};
		i2c0 {

			i2c0-xfer {

				rockchip,pins = <0x1 0xf 0x2 0xbb 0x1 0x10 0x2 0xbb>;
				linux,phandle = <0x32>;
				phandle = <0x32>;
			};
		};
		i2c1 {

			i2c1-xfer {

				rockchip,pins = <0x4 0x2 0x1 0xbb 0x4 0x1 0x1 0xbb>;
				linux,phandle = <0x39>;
				phandle = <0x39>;
			};
		};
		i2c2 {

			i2c2-xfer {

				rockchip,pins = <0x2 0x1 0x2 0xbc 0x2 0x0 0x2 0xbc>;
				linux,phandle = <0x3b>;
				phandle = <0x3b>;
			};
		};
		i2c3 {

			i2c3-xfer {

				rockchip,pins = <0x4 0x11 0x1 0xbb 0x4 0x10 0x1 0xbb>;
				linux,phandle = <0x3c>;
				phandle = <0x3c>;
			};
			i2c3_gpio {

				rockchip,pins = <0x4 0x11 0x0 0xbb 0x4 0x10 0x0 0xbb>;
			};
		};
		i2c4 {

			i2c4-xfer {

				rockchip,pins = <0x1 0xc 0x1 0xbb 0x1 0xb 0x1 0xbb>;
				linux,phandle = <0x7f>;
				phandle = <0x7f>;
			};
		};
		i2c5 {

			i2c5-xfer {

				rockchip,pins = <0x3 0xb 0x2 0xbb 0x3 0xa 0x2 0xbb>;
				linux,phandle = <0x3d>;
				phandle = <0x3d>;
			};
		};
		i2c6 {

			i2c6-xfer {

				rockchip,pins = <0x2 0xa 0x2 0xbb 0x2 0x9 0x2 0xbb>;
				linux,phandle = <0x3e>;
				phandle = <0x3e>;
			};
		};
		i2c7 {

			i2c7-xfer {

				rockchip,pins = <0x2 0x8 0x2 0xbb 0x2 0x7 0x2 0xbb>;
				linux,phandle = <0x3f>;
				phandle = <0x3f>;
			};
		};
		i2c8 {

			i2c8-xfer {

				rockchip,pins = <0x1 0x15 0x1 0xbb 0x1 0x14 0x1 0xbb>;
				linux,phandle = <0x86>;
				phandle = <0x86>;
			};
		};
		i2s0 {

			i2s0-8ch-bus {

				rockchip,pins = <0x3 0x18 0x1 0xbb 0x3 0x19 0x1 0xbb 0x3 0x1a 0x1 0xbb 0x3 0x1b 0x1 0xbb 0x3 0x1c 0x1 0xbb 0x3 0x1d 0x1 0xbb 0x3 0x1e 0x1 0xbb 0x3 0x1f 0x1 0xbb 0x4 0x0 0x1 0xbb>;
				linux,phandle = <0x9c>;
				phandle = <0x9c>;
			};
		};
		i2s1 {

			i2s1-2ch-bus {

				rockchip,pins = <0x4 0x3 0x1 0xbb 0x4 0x4 0x1 0xbb 0x4 0x5 0x1 0xbb 0x4 0x6 0x1 0xbb 0x4 0x7 0x1 0xbb>;
				linux,phandle = <0x9d>;
				phandle = <0x9d>;
			};
		};
		sdio0 {

			sdio0-bus1 {

				rockchip,pins = <0x2 0x14 0x1 0xb9>;
			};
			sdio0-bus4 {

				rockchip,pins = <0x2 0x14 0x1 0xb9 0x2 0x15 0x1 0xb9 0x2 0x16 0x1 0xb9 0x2 0x17 0x1 0xb9>;
				linux,phandle = <0x1e>;
				phandle = <0x1e>;
			};
			sdio0-cmd {

				rockchip,pins = <0x2 0x18 0x1 0xb9>;
				linux,phandle = <0x1f>;
				phandle = <0x1f>;
			};
			sdio0-clk {

				rockchip,pins = <0x2 0x19 0x1 0xbb>;
				linux,phandle = <0x20>;
				phandle = <0x20>;
			};
			sdio0-cd {

				rockchip,pins = <0x2 0x1a 0x1 0xb9>;
			};
			sdio0-pwr {

				rockchip,pins = <0x2 0x1b 0x1 0xb9>;
			};
			sdio0-bkpwr {

				rockchip,pins = <0x2 0x1c 0x1 0xb9>;
			};
			sdio0-wp {

				rockchip,pins = <0x0 0x3 0x1 0xb9>;
			};
			sdio0-int {

				rockchip,pins = <0x0 0x4 0x1 0xb9>;
			};
		};
		sdmmc {

			sdmmc-bus1 {

				rockchip,pins = <0x4 0x8 0x1 0xb9>;
			};
			sdmmc-bus4 {

				rockchip,pins = <0x4 0x8 0x1 0xb9 0x4 0x9 0x1 0xb9 0x4 0xa 0x1 0xb9 0x4 0xb 0x1 0xb9>;
				linux,phandle = <0x25>;
				phandle = <0x25>;
			};
			sdmmc-clk {

				rockchip,pins = <0x4 0xc 0x1 0xbb>;
				linux,phandle = <0x22>;
				phandle = <0x22>;
			};
			sdmmc-cmd {

				rockchip,pins = <0x4 0xd 0x1 0xb9>;
				linux,phandle = <0x23>;
				phandle = <0x23>;
			};
			sdmcc-cd {

				rockchip,pins = <0x0 0x7 0x1 0xb9>;
				linux,phandle = <0x24>;
				phandle = <0x24>;
			};
			sdmmc-wp {

				rockchip,pins = <0x0 0x8 0x1 0xb9>;
			};
		};
		spdif {

			spdif-bus {

				rockchip,pins = <0x4 0x15 0x1 0xbb>;
				linux,phandle = <0x9b>;
				phandle = <0x9b>;
			};
			spdif-bus-1 {

				rockchip,pins = <0x3 0x10 0x3 0xbb>;
			};
		};
		spi0 {

			spi0-clk {

				rockchip,pins = <0x3 0x6 0x2 0xb9>;
				linux,phandle = <0x47>;
				phandle = <0x47>;
			};
			spi0-cs0 {

				rockchip,pins = <0x3 0x7 0x2 0xb9>;
				linux,phandle = <0x4a>;
				phandle = <0x4a>;
			};
			spi0-cs1 {

				rockchip,pins = <0x3 0x8 0x2 0xb9>;
			};
			spi0-tx {

				rockchip,pins = <0x3 0x5 0x2 0xb9>;
				linux,phandle = <0x48>;
				phandle = <0x48>;
			};
			spi0-rx {

				rockchip,pins = <0x3 0x4 0x2 0xb9>;
				linux,phandle = <0x49>;
				phandle = <0x49>;
			};
		};
		spi1 {

			spi1-clk {

				rockchip,pins = <0x1 0x9 0x2 0xb9>;
				linux,phandle = <0x4b>;
				phandle = <0x4b>;
			};
			spi1-cs0 {

				rockchip,pins = <0x1 0xa 0x2 0xb9>;
				linux,phandle = <0x4e>;
				phandle = <0x4e>;
			};
			spi1-rx {

				rockchip,pins = <0x1 0x7 0x2 0xb9>;
				linux,phandle = <0x4d>;
				phandle = <0x4d>;
			};
			spi1-tx {

				rockchip,pins = <0x1 0x8 0x2 0xb9>;
				linux,phandle = <0x4c>;
				phandle = <0x4c>;
			};
		};
		spi2 {

			spi2-clk {

				rockchip,pins = <0x2 0xb 0x1 0xb9>;
				linux,phandle = <0x4f>;
				phandle = <0x4f>;
			};
			spi2-cs0 {

				rockchip,pins = <0x2 0xc 0x1 0xb9>;
				linux,phandle = <0x52>;
				phandle = <0x52>;
			};
			spi2-rx {

				rockchip,pins = <0x2 0x9 0x1 0xb9>;
				linux,phandle = <0x51>;
				phandle = <0x51>;
			};
			spi2-tx {

				rockchip,pins = <0x2 0xa 0x1 0xb9>;
				linux,phandle = <0x50>;
				phandle = <0x50>;
			};
		};
		spi3 {

			spi3-clk {

				rockchip,pins = <0x1 0x11 0x1 0xb9>;
				linux,phandle = <0x7a>;
				phandle = <0x7a>;
			};
			spi3-cs0 {

				rockchip,pins = <0x1 0x12 0x1 0xb9>;
				linux,phandle = <0x7d>;
				phandle = <0x7d>;
			};
			spi3-rx {

				rockchip,pins = <0x1 0xf 0x1 0xb9>;
				linux,phandle = <0x7c>;
				phandle = <0x7c>;
			};
			spi3-tx {

				rockchip,pins = <0x1 0x10 0x1 0xb9>;
				linux,phandle = <0x7b>;
				phandle = <0x7b>;
			};
		};
		spi4 {

			spi4-clk {

				rockchip,pins = <0x3 0x2 0x2 0xb9>;
				linux,phandle = <0x53>;
				phandle = <0x53>;
			};
			spi4-cs0 {

				rockchip,pins = <0x3 0x3 0x2 0xb9>;
				linux,phandle = <0x56>;
				phandle = <0x56>;
			};
			spi4-rx {

				rockchip,pins = <0x3 0x0 0x2 0xb9>;
				linux,phandle = <0x55>;
				phandle = <0x55>;
			};
			spi4-tx {

				rockchip,pins = <0x3 0x1 0x2 0xb9>;
				linux,phandle = <0x54>;
				phandle = <0x54>;
			};
		};
		spi5 {

			spi5-clk {

				rockchip,pins = <0x2 0x16 0x2 0xb9>;
				linux,phandle = <0x57>;
				phandle = <0x57>;
			};
			spi5-cs0 {

				rockchip,pins = <0x2 0x17 0x2 0xb9>;
				linux,phandle = <0x5a>;
				phandle = <0x5a>;
			};
			spi5-rx {

				rockchip,pins = <0x2 0x14 0x2 0xb9>;
				linux,phandle = <0x59>;
				phandle = <0x59>;
			};
			spi5-tx {

				rockchip,pins = <0x2 0x15 0x2 0xb9>;
				linux,phandle = <0x58>;
				phandle = <0x58>;
			};
		};
		tsadc {

			otp-gpio {

				rockchip,pins = <0x1 0x6 0x0 0xbb>;
				linux,phandle = <0x5e>;
				phandle = <0x5e>;
			};
			otp-out {

				rockchip,pins = <0x1 0x6 0x1 0xbb>;
				linux,phandle = <0x5f>;
				phandle = <0x5f>;
			};
		};
		uart0 {

			uart0-xfer {

				rockchip,pins = <0x2 0x10 0x1 0xb9 0x2 0x11 0x1 0xbb>;
				linux,phandle = <0x40>;
				phandle = <0x40>;
			};
			uart0-cts {

				rockchip,pins = <0x2 0x12 0x1 0xbb>;
				linux,phandle = <0x41>;
				phandle = <0x41>;
			};
			uart0-rts {

				rockchip,pins = <0x2 0x13 0x1 0xbb>;
				linux,phandle = <0xc9>;
				phandle = <0xc9>;
			};
		};
		uart1 {

			uart1-xfer {

				rockchip,pins = <0x3 0xc 0x2 0xb9 0x3 0xd 0x2 0xbb>;
				linux,phandle = <0x42>;
				phandle = <0x42>;
			};
		};
		uart2a {

			uart2a-xfer {

				rockchip,pins = <0x4 0x8 0x2 0xb9 0x4 0x9 0x2 0xbb>;
			};
		};
		uart2b {

			uart2b-xfer {

				rockchip,pins = <0x4 0x10 0x2 0xb9 0x4 0x11 0x2 0xbb>;
			};
		};
		uart2c {

			uart2c-xfer {

				rockchip,pins = <0x4 0x13 0x1 0xb9 0x4 0x14 0x1 0xbb>;
				linux,phandle = <0x43>;
				phandle = <0x43>;
			};
		};
		uart3 {

			uart3-xfer {

				rockchip,pins = <0x3 0xe 0x2 0xb9 0x3 0xf 0x2 0xbb>;
				linux,phandle = <0x44>;
				phandle = <0x44>;
			};
			uart3-cts {

				rockchip,pins = <0x3 0x12 0x2 0xbb>;
				linux,phandle = <0x45>;
				phandle = <0x45>;
			};
			uart3-rts {

				rockchip,pins = <0x3 0x13 0x2 0xbb>;
				linux,phandle = <0x46>;
				phandle = <0x46>;
			};
		};
		uart4 {

			uart4-xfer {

				rockchip,pins = <0x1 0x7 0x1 0xb9 0x1 0x8 0x1 0xbb>;
				linux,phandle = <0x7e>;
				phandle = <0x7e>;
			};
		};
		uarthdcp {

			uarthdcp-xfer {

				rockchip,pins = <0x4 0x15 0x2 0xb9 0x4 0x16 0x2 0xbb>;
			};
		};
		pwm0 {

			pwm0-pin {

				rockchip,pins = <0x4 0x12 0x1 0xbb>;
				linux,phandle = <0x8c>;
				phandle = <0x8c>;
			};
			vop0-pwm-pin {

				rockchip,pins = <0x4 0x12 0x2 0xbb>;
				linux,phandle = <0xab>;
				phandle = <0xab>;
			};
		};
		pwm1 {

			pwm1-pin {

				rockchip,pins = <0x4 0x16 0x1 0xbb>;
				linux,phandle = <0x8d>;
				phandle = <0x8d>;
			};
			vop1-pwm-pin {

				rockchip,pins = <0x4 0x12 0x3 0xbb>;
				linux,phandle = <0xa5>;
				phandle = <0xa5>;
			};
		};
		pwm2 {

			pwm2-pin {

				rockchip,pins = <0x1 0x13 0x1 0xbb>;
				linux,phandle = <0x8e>;
				phandle = <0x8e>;
			};
		};
		pwm3a {

			pwm3a-pin {

				rockchip,pins = <0x0 0x6 0x1 0xbb>;
				linux,phandle = <0x8f>;
				phandle = <0x8f>;
			};
		};
		pwm3b {

			pwm3b-pin {

				rockchip,pins = <0x1 0xe 0x1 0xbb>;
			};
		};
		edp {

			edp-hpd {

				rockchip,pins = <0x4 0x17 0x2 0xbb>;
				linux,phandle = <0xb3>;
				phandle = <0xb3>;
			};
		};
		hdmi {

			hdmi-i2c-xfer {

				rockchip,pins = <0x4 0x11 0x3 0xbb 0x4 0x10 0x3 0xbb>;
				linux,phandle = <0xac>;
				phandle = <0xac>;
			};
			hdmi-cec {

				rockchip,pins = <0x4 0x17 0x1 0xbb>;
			};
		};
		pcie {

			pci-clkreqn {

				rockchip,pins = <0x2 0x1a 0x2 0xbb>;
				linux,phandle = <0x8b>;
				phandle = <0x8b>;
			};
			pci-clkreqnb {

				rockchip,pins = <0x4 0x18 0x1 0xbb>;
			};
			pci-clkreqn-cpm {

				rockchip,pins = <0x2 0x1a 0x0 0xbb>;
			};
			pci-clkreqnb-cpm {

				rockchip,pins = <0x4 0x18 0x0 0xbb>;
			};
		};
		pmic {

			pmic-int-l {

				rockchip,pins = <0x1 0x15 0x0 0xb9>;
				linux,phandle = <0x35>;
				phandle = <0x35>;
			};
			pmic-dvs2 {

				rockchip,pins = <0x1 0x12 0x0 0xbd>;
				linux,phandle = <0x36>;
				phandle = <0x36>;
			};
		};
		usb2 {

			host-vbus-drv {

				rockchip,pins = <0x4 0x19 0x0 0xbb>;
				linux,phandle = <0xc1>;
				phandle = <0xc1>;
			};
		};
		fusb30x {

			fusb0-int {

				rockchip,pins = <0x1 0x2 0x0 0xb9 0x4 0x1a 0x0 0xb9>;
				linux,phandle = <0x80>;
				phandle = <0x80>;
			};
		};
		sdio-pwrseq {

			wifi-enable-h {

				rockchip,pins = <0x0 0xa 0x0 0xbb>;
				linux,phandle = <0xc0>;
				phandle = <0xc0>;
			};
		};
		wireless-bluetooth {

			uart0-gpios {

				rockchip,pins = <0x2 0x13 0x0 0xbb>;
				linux,phandle = <0xca>;
				phandle = <0xca>;
			};
		};
		lsm330_a {

			lsm330a-irq-gpio {

				rockchip,pins = <0x1 0x16 0x0 0xbb>;
				linux,phandle = <0x82>;
				phandle = <0x82>;
			};
		};
		lsm330_g {

			lsm330g-irq-gpio {

				rockchip,pins = <0x1 0x18 0x0 0xbb>;
				linux,phandle = <0x83>;
				phandle = <0x83>;
			};
		};
		ak8963 {

			ak8963-irq-gpio {

				rockchip,pins = <0x1 0x0 0x0 0xbb>;
				linux,phandle = <0x84>;
				phandle = <0x84>;
			};
		};
		cm3218 {

			cm3218-irq-gpio {

				rockchip,pins = <0x4 0x18 0x0 0xb9>;
				linux,phandle = <0x85>;
				phandle = <0x85>;
			};
		};
		hallsensor {

			mh248-irq-gpio {

				rockchip,pins = <0x0 0xd 0x0 0xbb>;
				linux,phandle = <0xcb>;
				phandle = <0xcb>;
			};
		};
		rockchip_headset {

			headset-gpio {

				rockchip,pins = <0x4 0x1c 0x0 0xbb>;
				linux,phandle = <0xcc>;
				phandle = <0xcc>;
			};
		};
		leds {

			led1-ctl {

				rockchip,pins = <0x1 0x17 0x0 0xb9>;
				linux,phandle = <0xcd>;
				phandle = <0xcd>;
			};
			led2-ctl {

				rockchip,pins = <0x0 0xc 0x0 0xb9>;
				linux,phandle = <0xce>;
				phandle = <0xce>;
			};
			led3-ctl {

				rockchip,pins = <0x1 0x1 0x0 0xb9>;
				linux,phandle = <0xcf>;
				phandle = <0xcf>;
			};
			led4-ctl {

				rockchip,pins = <0x0 0x8 0x0 0xb9>;
				linux,phandle = <0xd0>;
				phandle = <0xd0>;
			};
		};
		xgpio_beep {

			beep-gpio {

				rockchip,pins = <0x4 0x16 0x0 0xb9>;
				linux,phandle = <0xd1>;
				phandle = <0xd1>;
			};
		};
		xgpio_fan {

			fan-gpio {

				rockchip,pins = <0x1 0x12 0x0 0xb9>;
				linux,phandle = <0xd2>;
				phandle = <0xd2>;
			};
		};
		isp {

			cif-clkout {

				rockchip,pins = <0x2 0xb 0x3 0xbb>;
				linux,phandle = <0xd5>;
				phandle = <0xd5>;
			};
			isp-dvp-d0d7 {

				rockchip,pins = <0x2 0x0 0x3 0xbb 0x2 0x1 0x3 0xbb 0x2 0x2 0x3 0xbb 0x2 0x3 0x3 0xbb 0x2 0x4 0x3 0xbb 0x2 0x5 0x3 0xbb 0x2 0x6 0x3 0xbb 0x2 0x7 0x3 0xbb 0x2 0x8 0x3 0xbb 0x2 0x9 0x3 0xbb 0x2 0xa 0x3 0xbb>;
				linux,phandle = <0xd6>;
				phandle = <0xd6>;
			};
			isp-shutter {

				rockchip,pins = <0x1 0x1 0x1 0xbb 0x1 0x0 0x1 0xbb>;
			};
			isp-flash-trigger {

				rockchip,pins = <0x1 0x3 0x1 0xbb>;
				linux,phandle = <0xd9>;
				phandle = <0xd9>;
			};
			isp-prelight {

				rockchip,pins = <0x1 0x4 0x1 0xbb>;
				linux,phandle = <0xd7>;
				phandle = <0xd7>;
			};
			isp_flash_trigger_as_gpio {

				rockchip,pins = <0x0 0x11 0x0 0xbb>;
				linux,phandle = <0xd8>;
				phandle = <0xd8>;
			};
		};
		lcd-panel {

			lcd-panel-reset {

				rockchip,pins = <0x4 0x1e 0x0 0xb9>;
			};
		};
	};
	rockchip-suspend {

		compatible = "rockchip,pm-rk3399";
		status = "okay";
		rockchip,sleep-debug-en = <0x0>;
		rockchip,virtual-poweroff = <0x0>;
		rockchip,sleep-mode-config = <0xde>;
		rockchip,wakeup-config = <0x4>;
		rockchip,pwm-regulator-config = <0x4>;
		rockchip,power-ctrl = <0x34 0x11 0x0 0x34 0xe 0x0>;
	};
	energy-costs {

		rk3399-core-cost0 {

			busy-cost-data = <0x6c 0x2e 0x9f 0x43 0xd8 0x5a 0x10b 0x78 0x13e 0x99 0x177 0xc6 0x191 0xde>;
			idle-cost-data = <0x6 0x6 0x0 0x0>;
			linux,phandle = <0xc>;
			phandle = <0xc>;
		};
		rk3399-core-cost1 {

			busy-cost-data = <0xd2 0x81 0x134 0xb8 0x1a3 0xf6 0x206 0x14f 0x269 0x1ac 0x2d8 0x23d 0x33b 0x2d4 0x39d 0x384 0x400 0x454>;
			idle-cost-data = <0xf 0xf 0x0 0x0>;
			linux,phandle = <0x10>;
			phandle = <0x10>;
		};
		rk3399-cluster-cost0 {

			busy-cost-data = <0x6c 0x2e 0x9f 0x43 0xd8 0x5a 0x10b 0x78 0x13e 0x99 0x177 0xc6 0x191 0xde>;
			idle-cost-data = <0x38 0x38 0x38 0x38>;
			linux,phandle = <0xd>;
			phandle = <0xd>;
		};
		rk3399-cluster-cost1 {

			busy-cost-data = <0xd2 0x81 0x134 0xb8 0x1a3 0xf6 0x206 0x14f 0x269 0x1ac 0x2d8 0x23d 0x33b 0x2d4 0x39d 0x384 0x400 0x454>;
			idle-cost-data = <0x41 0x41 0x41 0x41>;
			linux,phandle = <0x11>;
			phandle = <0x11>;
		};
	};
	opp-table0 {

		compatible = "operating-points-v2";
		opp-shared;
		linux,phandle = <0xb>;
		phandle = <0xb>;
		opp@408000000 {

			opp-hz = <0x0 0x18519600>;
			opp-microvolt = <0xc3500>;
			clock-latency-ns = <0x9c40>;
		};
		opp@600000000 {

			opp-hz = <0x0 0x23c34600>;
			opp-microvolt = <0xc3500>;
			clock-latency-ns = <0x9c40>;
		};
		opp@816000000 {

			opp-hz = <0x0 0x30a32c00>;
			opp-microvolt = <0xcf850>;
			clock-latency-ns = <0x9c40>;
			opp-suspend;
		};
		opp@1008000000 {

			opp-hz = <0x0 0x3c14dc00>;
			opp-microvolt = <0xe1d48>;
			clock-latency-ns = <0x9c40>;
		};
		opp@1200000000 {

			opp-hz = <0x0 0x47868c00>;
			opp-microvolt = <0xf4240>;
			clock-latency-ns = <0x9c40>;
		};
		opp@1416000000 {

			opp-hz = <0x0 0x54667200>;
			opp-microvolt = <0x112a88>;
			clock-latency-ns = <0x9c40>;
		};
	};
	opp-table1 {

		compatible = "operating-points-v2";
		opp-shared;
		linux,phandle = <0xf>;
		phandle = <0xf>;
		opp@408000000 {

			opp-hz = <0x0 0x18519600>;
			opp-microvolt = <0xc3500>;
			clock-latency-ns = <0x9c40>;
		};
		opp@600000000 {

			opp-hz = <0x0 0x23c34600>;
			opp-microvolt = <0xc3500>;
			clock-latency-ns = <0x9c40>;
		};
		opp@816000000 {

			opp-hz = <0x0 0x30a32c00>;
			opp-microvolt = <0xc96a8>;
			clock-latency-ns = <0x9c40>;
			opp-suspend;
		};
		opp@1008000000 {

			opp-hz = <0x0 0x3c14dc00>;
			opp-microvolt = <0xd59f8>;
			clock-latency-ns = <0x9c40>;
		};
		opp@1200000000 {

			opp-hz = <0x0 0x47868c00>;
			opp-microvolt = <0xe7ef0>;
			clock-latency-ns = <0x9c40>;
		};
		opp@1416000000 {

			opp-hz = <0x0 0x54667200>;
			opp-microvolt = <0xfa3e8>;
			clock-latency-ns = <0x9c40>;
		};
		opp@1608000000 {

			opp-hz = <0x0 0x5fd82200>;
			opp-microvolt = <0x10c8e0>;
			clock-latency-ns = <0x9c40>;
		};
		opp@1800000000 {

			opp-hz = <0x0 0x6b49d200>;
			opp-microvolt = <0x124f80>;
			clock-latency-ns = <0x9c40>;
		};
	};
	opp-table2 {

		compatible = "operating-points-v2";
		linux,phandle = <0x9e>;
		phandle = <0x9e>;
		opp@200000000 {

			opp-hz = <0x0 0xbebc200>;
			opp-microvolt = <0xc3500>;
		};
		opp@297000000 {

			opp-hz = <0x0 0x11b3dc40>;
			opp-microvolt = <0xc3500>;
		};
		opp@400000000 {

			opp-hz = <0x0 0x17d78400>;
			opp-microvolt = <0xc96a8>;
		};
		opp@500000000 {

			opp-hz = <0x0 0x1dcd6500>;
			opp-microvolt = <0xd59f8>;
		};
		opp@594000000 {

			opp-hz = <0x0 0x2367b880>;
			opp-microvolt = <0xe1d48>;
		};
		opp@800000000 {

			opp-hz = <0x0 0x2faf0800>;
			opp-microvolt = <0x10c8e0>;
		};
	};
	opp-table3 {

		compatible = "operating-points-v2";
		linux,phandle = <0x93>;
		phandle = <0x93>;
		opp@200000000 {

			opp-hz = <0x0 0xbebc200>;
			opp-microvolt = <0xc96a8>;
		};
		opp@297000000 {

			opp-hz = <0x0 0x11b3dc40>;
			opp-microvolt = <0xcf850>;
		};
		opp@400000000 {

			opp-hz = <0x0 0x17d78400>;
			opp-microvolt = <0xcf850>;
		};
		opp@594000000 {

			opp-hz = <0x0 0x2367b880>;
			opp-microvolt = <0xdbba0>;
		};
		opp@800000000 {

			opp-hz = <0x0 0x2faf0800>;
			opp-microvolt = <0xdbba0>;
		};
	};
	backlight {

		status = "okay";
		compatible = "pwm-backlight";
		pwms = <0xbe 0x0 0x61a8 0x0>;
		brightness-levels = <0x0 0x1 0x2 0x3 0x4 0x5 0x6 0x7 0x8 0x9 0xa 0xb 0xc 0xd 0xe 0xf 0x10 0x11 0x12 0x13 0x14 0x15 0x16 0x17 0x18 0x19 0x1a 0x1b 0x1c 0x1d 0x1e 0x1f 0x20 0x21 0x22 0x23 0x24 0x25 0x26 0x27 0x28 0x29 0x2a 0x2b 0x2c 0x2d 0x2e 0x2f 0x30 0x31 0x32 0x33 0x34 0x35 0x36 0x37 0x38 0x39 0x3a 0x3b 0x3c 0x3d 0x3e 0x3f 0x40 0x41 0x42 0x43 0x44 0x45 0x46 0x47 0x48 0x49 0x4a 0x4b 0x4c 0x4d 0x4e 0x4f 0x50 0x51 0x52 0x53 0x54 0x55 0x56 0x57 0x58 0x59 0x5a 0x5b 0x5c 0x5d 0x5e 0x5f 0x60 0x61 0x62 0x63 0x64 0x65 0x66 0x67 0x68 0x69 0x6a 0x6b 0x6c 0x6d 0x6e 0x6f 0x70 0x71 0x72 0x73 0x74 0x75 0x76 0x77 0x78 0x79 0x7a 0x7b 0x7c 0x7d 0x7e 0x7f 0x80 0x81 0x82 0x83 0x84 0x85 0x86 0x87 0x88 0x89 0x8a 0x8b 0x8c 0x8d 0x8e 0x8f 0x90 0x91 0x92 0x93 0x94 0x95 0x96 0x97 0x98 0x99 0x9a 0x9b 0x9c 0x9d 0x9e 0x9f 0xa0 0xa1 0xa2 0xa3 0xa4 0xa5 0xa6 0xa7 0xa8 0xa9 0xaa 0xab 0xac 0xad 0xae 0xaf 0xb0 0xb1 0xb2 0xb3 0xb4 0xb5 0xb6 0xb7 0xb8 0xb9 0xba 0xbb 0xbc 0xbd 0xbe 0xbf 0xc0 0xc1 0xc2 0xc3 0xc4 0xc5 0xc6 0xc7 0xc8 0xc9 0xca 0xcb 0xcc 0xcd 0xce 0xcf 0xd0 0xd1 0xd2 0xd3 0xd4 0xd5 0xd6 0xd7 0xd8 0xd9 0xda 0xdb 0xdc 0xdd 0xde 0xdf 0xe0 0xe1 0xe2 0xe3 0xe4 0xe5 0xe6 0xe7 0xe8 0xe9 0xea 0xeb 0xec 0xed 0xee 0xef 0xf0 0xf1 0xf2 0xf3 0xf4 0xf5 0xf6 0xf7 0xf8 0xf9 0xfa 0xfb 0xfc 0xfd 0xfe 0xff>;
		default-brightness-level = <0xc8>;
		linux,phandle = <0xb1>;
		phandle = <0xb1>;
	};
	external-gmac-clock {

		compatible = "fixed-clock";
		clock-frequency = <0x7735940>;
		clock-output-names = "clkin_gmac";
		#clock-cells = <0x0>;
		linux,phandle = <0x1b>;
		phandle = <0x1b>;
	};
	sdio-pwrseq {

		compatible = "mmc-pwrseq-simple";
		clocks = <0xbf 0x1>;
		clock-names = "ext_clock";
		pinctrl-names = "default";
		pinctrl-0 = <0xc0>;
		reset-gpios = <0x3a 0xa 0x1>;
		linux,phandle = <0x1d>;
		phandle = <0x1d>;
	};
	vcc3v3-sys {

		compatible = "regulator-fixed";
		regulator-name = "vcc3v3_sys";
		regulator-always-on;
		regulator-boot-on;
		regulator-min-microvolt = <0x325aa0>;
		regulator-max-microvolt = <0x325aa0>;
		linux,phandle = <0x37>;
		phandle = <0x37>;
	};
	vcc5v0-host-regulator {

		compatible = "regulator-fixed";
		enable-active-high;
		gpio = <0x81 0x19 0x0>;
		pinctrl-names = "default";
		pinctrl-0 = <0xc1>;
		regulator-name = "vcc5v0_host";
		regulator-always-on;
		linux,phandle = <0x99>;
		phandle = <0x99>;
	};
	vcc5v0-sys {

		compatible = "regulator-fixed";
		regulator-name = "vcc5v0_sys";
		regulator-always-on;
		regulator-boot-on;
		regulator-min-microvolt = <0x4c4b40>;
		regulator-max-microvolt = <0x4c4b40>;
		linux,phandle = <0x33>;
		phandle = <0x33>;
	};
	vcc-phy-regulator {

		compatible = "regulator-fixed";
		regulator-name = "vcc_phy";
		regulator-always-on;
		regulator-boot-on;
		linux,phandle = <0x19>;
		phandle = <0x19>;
	};
	vdd-log {

		compatible = "pwm-regulator";
		pwms = <0xc2 0x0 0x61a8 0x1>;
		regulator-name = "vdd_log";
		regulator-min-microvolt = <0xc3500>;
		regulator-max-microvolt = <0x155cc0>;
		regulator-always-on;
		regulator-boot-on;
		rockchip,pwm_id = <0x2>;
		rockchip,pwm_voltage = <0xf4240>;
	};
	rt5651-sound {

		compatible = "simple-audio-card";
		simple-audio-card,format = "i2s";
		simple-audio-card,name = "realtek,rt5651-codec";
		simple-audio-card,mclk-fs = <0x100>;
		simple-audio-card,widgets = "Microphone", "Mic Jack", "Headphone", "Headphone Jack";
		simple-audio-card,routing = "Mic Jack", "MICBIAS1", "IN1P", "Mic Jack", "Headphone Jack", "HPOL", "Headphone Jack", "HPOR";
		simple-audio-card,cpu {

			sound-dai = <0xc3>;
		};
		simple-audio-card,codec {

			sound-dai = <0xc4>;
		};
	};
	spdif-sound {

		status = "okay";
		compatible = "simple-audio-card";
		simple-audio-card,name = "ROCKCHIP,SPDIF";
		simple-audio-card,cpu {

			sound-dai = <0xc5>;
		};
		simple-audio-card,codec {

			sound-dai = <0xc6>;
		};
	};
	spdif-out {

		status = "okay";
		compatible = "linux,spdif-dit";
		#sound-dai-cells = <0x0>;
		linux,phandle = <0xc6>;
		phandle = <0xc6>;
	};
	dw-hdmi-audio {

		status = "disabled";
		compatible = "rockchip,dw-hdmi-audio";
		#sound-dai-cells = <0x0>;
	};
	hdmi-sound {

		status = "okay";
		compatible = "simple-audio-card";
		simple-audio-card,format = "i2s";
		simple-audio-card,mclk-fs = <0x100>;
		simple-audio-card,name = "rockchip,hdmi";
		simple-audio-card,cpu {

			sound-dai = <0xc7>;
		};
		simple-audio-card,codec {

			sound-dai = <0xc8>;
		};
	};
	wireless-wlan {

		compatible = "wlan-platdata";
		rockchip,grf = <0x17>;
		wifi_chip_type = "ap6356";
		sdio_vref = <0x708>;
		WIFI,host_wake_irq = <0x3a 0x3 0x0>;
		status = "okay";
	};
	wireless-bluetooth {

		compatible = "bluetooth-platdata";
		clocks = <0xbf 0x1>;
		clock-names = "ext_clock";
		uart_rts_gpios = <0x8a 0x13 0x1>;
		pinctrl-names = "default", "rts_gpio";
		pinctrl-0 = <0xc9>;
		pinctrl-1 = <0xca>;
		BT,reset_gpio = <0x3a 0x9 0x0>;
		BT,wake_gpio = <0x8a 0x1a 0x0>;
		BT,wake_host_irq = <0x3a 0x4 0x0>;
		status = "okay";
	};
	hall-mh248 {

		compatible = "hall-mh248";
		pinctrl-names = "default";
		pinctrl-0 = <0xcb>;
		irq-gpio = <0x3a 0xd 0x3>;
		hall-active = <0x1>;
		status = "disabled";
	};
	rockchip_headset {

		compatible = "rockchip_headset";
		pinctrl-names = "default";
		pinctrl-0 = <0xcc>;
		headset_gpio = <0x81 0x1c 0x1>;
		rockchip,headset_wakeup = <0x0>;
		status = "okay";
	};
	leds {

		compatible = "gpio-leds";
		led@1 {

			pinctrl-names = "default";
			pinctrl-0 = <0xcd>;
			label = "led1";
			gpios = <0x34 0x17 0x1>;
			linux,default-trigger = "heartbeat";
			default-state = "off";
		};
		led@2 {

			pinctrl-names = "default";
			pinctrl-0 = <0xce>;
			label = "led2";
			gpios = <0x3a 0xc 0x1>;
			default-state = "off";
		};
		led@3 {

			pinctrl-names = "default";
			pinctrl-0 = <0xcf>;
			label = "led3";
			gpios = <0x34 0x1 0x1>;
			default-state = "off";
		};
		led@4 {

			pinctrl-names = "default";
			pinctrl-0 = <0xd0>;
			label = "led4";
			gpios = <0x3a 0x8 0x1>;
			default-state = "off";
		};
	};
	xgpio_beep {

		compatible = "9tripod,xgpio";
		pinctrl-names = "default";
		pinctrl-0 = <0xd1>;
		gpio = <0x81 0x16 0x0>;
		status = "okay";
	};
	xgpio_fan {

		compatible = "9tripod,xgpio";
		pinctrl-names = "default";
		pinctrl-0 = <0xd2>;
		gpio = <0x34 0x12 0x0>;
		status = "okay";
	};
	chosen {

		bootargs = "earlycon=uart8250,mmio32,0xff1a0000 swiotlb=1";
	};
	ramoops_mem {

		reg = <0x0 0x110000 0x0 0xf0000>;
		reg-names = "ramoops_mem";
		linux,phandle = <0xd3>;
		phandle = <0xd3>;
	};
	ramoops {

		compatible = "ramoops";
		record-size = <0x0 0x20000>;
		console-size = <0x0 0x80000>;
		ftrace-size = <0x0 0x0>;
		pmsg-size = <0x0 0x50000>;
		memory-region = <0xd3>;
	};
	fiq-debugger {

		compatible = "rockchip,fiq-debugger";
		rockchip,serial-id = <0x2>;
		rockchip,signal-irq = <0xb6>;
		rockchip,wake-irq = <0x0>;
		rockchip,irq-mode-enable = <0x1>;
		rockchip,baudrate = <0x1c200>;
		pinctrl-names = "default";
		pinctrl-0 = <0x43>;
	};
	reserved-memory {

		#address-cells = <0x2>;
		#size-cells = <0x2>;
		ranges;
		drm-logo@00000000 {

			compatible = "rockchip,drm-logo";
			reg = <0x0 0x0 0x0 0x0>;
			linux,phandle = <0xb8>;
			phandle = <0xb8>;
		};
	};
	rockchip-key {

		compatible = "rockchip,key";
		status = "okay";
		io-channels = <0xd4 0x1>;
		power-key {

			gpios = <0x3a 0x5 0x1>;
			linux,code = <0x74>;
			label = "power";
			gpio-key,wakeup;
		};
		vol-up-key {

			linux,code = <0x73>;
			label = "volume up";
			rockchip,adc_value = <0x1>;
		};
		vol-down-key {

			linux,code = <0x72>;
			label = "volume down";
			rockchip,adc_value = <0xaa>;
		};
		back-key {

			linux,code = <0x9e>;
			label = "back";
			rockchip,adc_value = <0x230>;
		};
		menu-key {

			linux,code = <0x8b>;
			label = "menu";
			rockchip,adc_value = <0x2ee>;
		};
	};
	isp@ff910000 {

		compatible = "rockchip,rk3399-isp", "rockchip,isp";
		reg = <0x0 0xff910000 0x0 0x4000>;
		interrupts = <0x0 0x2b 0x4 0x0>;
		clocks = <0x8 0x89 0x8 0x89 0x8 0xa4 0x8 0x77 0x8 0xe7 0x8 0xe9 0x8 0x1e1 0x8 0x1e3 0x8 0x6e 0x8 0xa5>;
		clock-names = "clk_cif_out", "clk_cif_pll", "pclk_dphytxrx", "pclk_dphy_ref", "aclk_isp0_noc", "aclk_isp0_wrapper", "hclk_isp0_noc", "hclk_isp0_wrapper", "clk_isp0", "pclk_dphyrx";
		pinctrl-names = "cif_clkout", "isp_dvp8bit0", "isp_mipi_fl", "isp_mipi_fl_prefl", "isp_flash_as_gpio", "isp_flash_as_trigger_out";
		pinctrl-0 = <0xd5>;
		pinctrl-1 = <0xd6>;
		pinctrl-2 = <0xd5>;
		pinctrl-3 = <0xd7>;
		pinctrl-4 = <0xd8>;
		pinctrl-5 = <0xd9>;
		rockchip,isp,mipiphy = <0x2>;
		rockchip,isp,cifphy = <0x1>;
		rockchip,isp,dsiphy,reg = <0xff968000 0x8000>;
		rockchip,grf = <0x17>;
		rockchip,cru = <0x8>;
		rockchip,gpios = <0x8a 0xc 0x0>;
		rockchip,isp,iommu-enable = <0x1>;
		power-domains = <0x18 0x13>;
		iommus = <0xda>;
		status = "okay";
	};
	isp@ff920000 {

		compatible = "rockchip,rk3399-isp", "rockchip,isp";
		reg = <0x0 0xff920000 0x0 0x4000>;
		interrupts = <0x0 0x2c 0x4 0x0>;
		clocks = <0x8 0xe8 0x8 0xea 0x8 0x1e2 0x8 0x1e4 0x8 0x6f 0x8 0x89 0x8 0x89 0x8 0xa4 0x8 0x77 0x8 0x17b 0x8 0xa5 0x8 0x171 0x8 0x78>;
		clock-names = "aclk_isp1_noc", "aclk_isp1_wrapper", "hclk_isp1_noc", "hclk_isp1_wrapper", "clk_isp1", "clk_cif_out", "clk_cif_pll", "pclk_dphytxrx", "pclk_dphy_ref", "pclk_isp1", "pclk_dphyrx", "pclk_mipi_dsi", "mipi_dphy_cfg";
		pinctrl-names = "cif_clkout", "isp_dvp8bit0", "isp_mipi_fl", "isp_mipi_fl_prefl", "isp_flash_as_gpio", "isp_flash_as_trigger_out";
		pinctrl-0 = <0xd5>;
		pinctrl-1 = <0xd6>;
		pinctrl-2 = <0xd5>;
		pinctrl-3 = <0xd7>;
		pinctrl-4 = <0xd8>;
		pinctrl-5 = <0xd9>;
		rockchip,isp,mipiphy = <0x2>;
		rockchip,isp,cifphy = <0x1>;
		rockchip,isp,dsiphy,reg = <0xff968000 0x8000>;
		rockchip,grf = <0x17>;
		rockchip,cru = <0x8>;
		rockchip,gpios = <0x8a 0xc 0x0>;
		rockchip,isp,iommu-enable = <0x1>;
		power-domains = <0x18 0x14>;
		iommus = <0xdb>;
		status = "okay";
	};
	uboot-charge {

		compatible = "rockchip,uboot-charge";
		rockchip,uboot-charge-on = <0x1>;
		rockchip,android-charge-on = <0x0>;
	};
	hdmi-dp-sound {

		status = "disabled";
		compatible = "rockchip,rk3399-hdmi-dp";
		rockchip,cpu = <0xc7>;
		rockchip,codec = <0xc8 0xdc>;
	};
	test-power {

		status = "okay";
	};
	rt5651 {

		status = "okay";
	};
};
